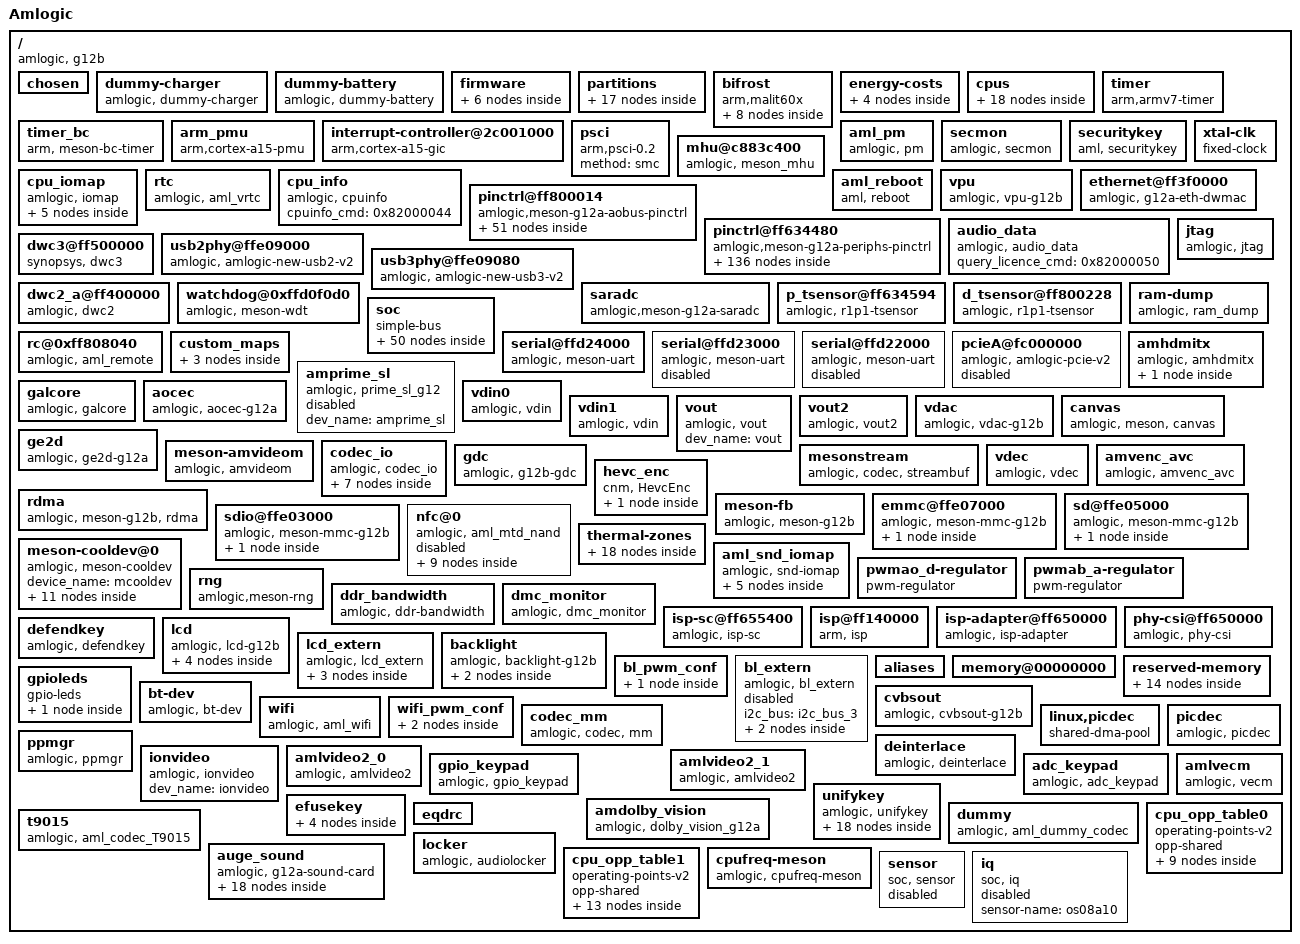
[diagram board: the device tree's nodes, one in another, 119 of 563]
/dts-v1/;

/memreserve/	0x0000000009fe5000 0x0000000000018000;
/ {
	model = "Amlogic";
	amlogic-dt-id = "g12b_w400_b";
	compatible = "amlogic, g12b";
	interrupt-parent = <0x01>;
	#address-cells = <0x01>;
	#size-cells = <0x01>;

	// 内核启动参数，影响系统初始化行为
	chosen {
		bootargs = "
		// 指定 init 程序路径
		init=/init
		// 串口输出设置
		console=ttyS0,115200
		// 禁用串口挂起
		no_console_suspend
		// 启用早期串口调试
		earlycon=aml-uart,0xff803000
		// 启用崩溃日志记录
		ramoops.pstore_en=1
		// 设置记录大小
		ramoops.record_size=0x8000
	 	// 设置控制台日志大小
		ramoops.console_size=0x4000
		// HDR 显示策略
		hdr_policy=1
		// 启用 USB OTG 模式
		hdr_priority= otg_device=1
		// 设置重启模式
		reboot_mode_android=normal
		// logo 显示设置
		logo=osd0,loaded,0x3d800000
		// 帧缓冲区分辨率
		fb_width=1920 fb_height=1080
		// 视频输出设置
		vout=576cvbs,enable
		// LCD 面板类型与控制参数
		panel_type=lcd_2 lcd_ctrl=0x00000083
		// HDMI 输出设置
		hdmitx=,444,12bit hdmimode=1080p60hz hdmichecksum=0x00000000
		// Dolby Vision 设置
		dolby_vision_on=0
		// 分数帧率策略
		frac_rate_policy=1
		// 启用 EDID 读取
		hdmi_read_edid=1
		// CVBS 模式
		cvbsmode=576cvbs
		// OSD 和视频反转设置
		osd_reverse=0 video_reverse=0
		// IRQ 检查开关
		irq_check_en=0
		// SELinux 强制模式
		androidboot.selinux=enforcing
		// 是否首次启动
		androidboot.firstboot=0
		// 禁用 JTAG
		jtag=disable
		// 硬件平台标识
		androidboot.hardware=amlogic
		// 启动引导程序版本
		androidboot.bootloader=U-Boot 2015.01
		 // 基带信息
		androidboot.build.expect.baseband=N/A
		// 设备序列号
		androidboot.serialno=DZXB3P4213004936
		// MAC 地址
		mac=4C:91:7A:5F:F8:5A androidboot.mac=4C:91:7A:5F:F8:5A
		// OEM 自定义参数
		androidboot.oem.key1=ATV00104319
		// RPMB 安全存储状态
		androidboot.rpmb_state=1
		// 根文件系统挂载为只读
		ro
		// 等待根文件系统挂载
		rootwait
		// 跳过 initramfs 阶段
		skip_initramfs
		// DTBO 索引
		androidboot.dtbo_idx=0
		 // 指定根文件系统位置和构建类型
		--cmdline root=/dev/mmcblk0p18 buildvariant=user";
	};

	// 虚拟充电器
	dummy-charger {
		// 启用虚拟充电器设备（用于无电池设备）
		status = "okay";
		// 兼容字符串，匹配驱动
		compatible = "amlogic, dummy-charger";
	};

	// 虚拟电池
	dummy-battery {
		// 启用虚拟电池设备
		status = "okay";
		compatible = "amlogic, dummy-battery";
	};

	// 固件分区挂载信息
	firmware {

		android {
			compatible = "android,firmware";

			vbmeta {
				// Android Verified Boot 元数据配置
				compatible = "android,vbmeta";
				parts = "vbmeta,boot,system,vendor";
				by_name_prefix = "/dev/block";
			};

			fstab {
				compatible = "android,fstab";

				vendor {
					// 挂载 vendor 分区
					compatible = "android,vendor";
					dev = "/dev/block/vendor";
					type = "ext4";
					mnt_flags = "ro,barrier=1,inode_readahead_blks=8";
					fsmgr_flags = "wait";
				};

				product {
					// 挂载 product 分区
					compatible = "android,product";
					dev = "/dev/block/product";
					type = "ext4";
					mnt_flags = "ro,barrier=1,inode_readahead_blks=8";
					fsmgr_flags = "wait";
				};

				odm {
					// 挂载 odm 分区
					compatible = "android,odm";
					dev = "/dev/block/odm";
					type = "ext4";
					mnt_flags = "ro,barrier=1,inode_readahead_blks=8";
					fsmgr_flags = "wait";
				};
			};
		};
	};

	// 分区信息
	partitions {
		// 总分区数量（十六进制 0x11 = 十进制 17）
		parts = <0x11>;

		// 每个 part-x 都是一个分区的 phandle 引用
		part-0 = <0x02>;  // logo 分区
		part-1 = <0x03>;  // recovery 分区
		part-2 = <0x04>;  // misc 分区
		part-3 = <0x05>;  // dtbo 分区
		part-4 = <0x06>;  // cri_data 分区
		part-5 = <0x07>;  // param 分区
		part-6 = <0x08>;  // boot 分区
		part-7 = <0x09>;  // rsv 保留分区
		part-8 = <0x0a>;  // metadata 分区
		part-9 = <0x0b>;  // vbmeta 分区
		part-10 = <0x0c>; // tee 安全执行环境分区
		part-11 = <0x0d>; // vendor 分区
		part-12 = <0x0e>; // odm 分区
		part-13 = <0x0f>; // system 系统分区
		part-14 = <0x10>; // product 产品分区
		part-15 = <0x11>; // cache 缓存分区
		part-16 = <0x12>; // data 用户数据分区

		// partitions 节点的 phandle 引用
		phandle = <0xa4>;

		// 以下是每个分区的定义，包括名称、大小、掩码等
		logo {
			pname = "logo";              // 分区名称
			size = <0x00 0x800000>;      // 分区大小（8MB）
			mask = <0x01>;               // 掩码（访问权限或标志）
			phandle = <0x02>;            // 分区引用 ID
		};

		recovery {
			pname = "recovery";
			size = <0x00 0x1800000>;     // 24MB
			mask = <0x01>;
			phandle = <0x03>;
		};

		misc {
			pname = "misc";
			size = <0x00 0x800000>;      // 8MB
			mask = <0x01>;
			phandle = <0x04>;
		};

		dtbo {
			pname = "dtbo";              // 设备树覆盖分区
			size = <0x00 0x800000>;
			mask = <0x01>;
			phandle = <0x05>;
		};

		cri_data {
			pname = "cri_data";          // Critical data 分区
			size = <0x00 0x800000>;
			mask = <0x02>;
			phandle = <0x06>;
		};

		rsv {
			pname = "rsv";               // 保留分区
			size = <0x00 0x1000000>;
			mask = <0x01>;
			phandle = <0x09>;
		};

		metadata {
			pname = "metadata";          // 元数据分区
			size = <0x00 0x1000000>;
			mask = <0x01>;
			phandle = <0x0a>;
		};

		vbmeta {
			pname = "vbmeta";            // Verified Boot 元数据
			size = <0x00 0x200000>;      // 2MB
			mask = <0x01>;
			phandle = <0x0b>;
		};

		param {
			pname = "param";             // 参数配置分区
			size = <0x00 0x1000000>;     // 16MB
			mask = <0x02>;
			phandle = <0x07>;
		};

		boot {
			pname = "boot";              // 启动镜像分区
			size = <0x00 0x1000000>;     // 16MB
			mask = <0x01>;
			phandle = <0x08>;
		};

		tee {
			pname = "tee";              // TrustZone 分区
			size = <0x00 0x2000000>;    // 32MB
			mask = <0x01>;
			phandle = <0x0c>;
		};

		vendor {
			pname = "vendor";           // 供应商分区
			size = <0x00 0x40000000>;   // 1GB
			mask = <0x01>;
			phandle = <0x0d>;
		};

		odm {
			pname = "odm";              // OEM Device Manufacturer 分区
			size = <0x00 0x8000000>;    // 128MB
			mask = <0x01>;
			phandle = <0x0e>;
		};

		system {
			pname = "system";           // Android 系统分区
			size = <0x00 0x80000000>;   // 2GB
			mask = <0x01>;
			phandle = <0x0f>;
		};

		product {
			pname = "product";          // 产品定制分区
			size = <0x00 0x8000000>;    // 128MB
			mask = <0x01>;
			phandle = <0x10>;
		};

		cache {
			pname = "cache";            // 缓存分区
			size = <0x00 0x60000000>;   // 1.5GB
			mask = <0x02>;
			phandle = <0x11>;
		};

		data {
			pname = "data";             // 用户数据分区
			size = <0xffffffff 0xffffffff>;// 动态分配最大空间
			mask = <0x04>;
			phandle = <0x12>;
		};
	};

	// Amlogic G12B 平台上的 Mali GPU（Midgard 架构）的硬件资源、时钟、DVFS 配置等。
	bifrost {
		// 兼容字符串，匹配驱动（Mali-T60x/T6xx/Midgard 系列）
		compatible = "arm,malit60x\0arm,malit6xx\0arm,mali-midgard";

		// cooling-cells 表示散热设备的参数数量
		#cooling-cells = <0x02>;

		// GPU 寄存器地址映射（多个区域）
		reg = <0xffe40000 0x4000 0xffd01000 0x1000 0xff800000 0x1000 0xff63c000 0x1000 0xffd01000 0x1000>;

		// 中断控制器引用
		interrupt-parent = <0x01>;

		// GPU、MMU、JOB 的中断号及类型
		interrupts = <0x00 0xa0 0x04 0x00 0xa1 0x04 0x00 0xa2 0x04>;
		interrupt-names = "GPU\0MMU\0JOB";

		// PP（Pixel Processor）数量
		num_of_pp = <0x02>;

		// SCMPP（Shader Core Multi PP）配置
		sc_mpp = <0x01>;

		// GPU 时钟源配置（引用 clock-controller）
		clocks = <0x13 0x83 0x13 0x07>;
		clock-names = "gpu_mux\0gp0_pll";

		// DVFS 表引用（phandle）
		tbl = <0x14 0x15 0x16 0x17 0x18 0x18>;

		// 系统一致性设置（通常为 0 表示关闭）
		system-coherency = <0x00>;

		// 节点引用句柄
		phandle = <0xa5>;

		// 以下是不同频率下的 DVFS 配置（动态电压频率调整）
		clk125_cfg {
			clk_freq = <0x7735940>;           // 125MHz
			clk_parent = "fclk_div4";         // 时钟父源
			clkp_freq = <0x1dcd6500>;         // 父源频率（500MHz）
			clk_reg = <0xa03>;                // 时钟寄存器地址
			voltage = <0x47e>;                // 电压值（单位微伏）
			keep_count = <0x05>;              // 保持周期
			threshold = <0x1e 0x78>;          // 温度或负载阈值
			phandle = <0xa6>;
		};

		dvfs250_cfg {
			clk_freq = <0xee6b280>;           // 250MHz
			clk_parent = "fclk_div4";
			clkp_freq = <0x1dcd6500>;
			clk_reg = <0xa01>;
			voltage = <0x47e>;
			keep_count = <0x05>;
			threshold = <0x50 0xaa>;
			phandle = <0xa7>;
		};

		dvfs285_cfg {
			clk_freq = <0x1107a76d>;          // 285MHz
			clk_parent = "fclk_div7";
			clkp_freq = <0x1107a76d>;
			clk_reg = <0xe00>;
			voltage = <0x47e>;
			keep_count = <0x05>;
			threshold = <0x64 0xbe>;
			phandle = <0x14>;
		};

		dvfs400_cfg {
			clk_freq = <0x17d78400>;          // 400MHz
			clk_parent = "fclk_div5";
			clkp_freq = <0x17d78400>;
			clk_reg = <0xc00>;
			voltage = <0x47e>;
			keep_count = <0x05>;
			threshold = <0x98 0xcf>;
			phandle = <0x15>;
		};

		dvfs500_cfg {
			clk_freq = <0x1dcd6500>;          // 500MHz
			clk_parent = "fclk_div4";
			clkp_freq = <0x1dcd6500>;
			clk_reg = <0xa00>;
			voltage = <0x47e>;
			keep_count = <0x05>;
			threshold = <0xb4 0xdc>;
			phandle = <0x16>;
		};

		dvfs666_cfg {
			clk_freq = <0x27bc86aa>;          // 666MHz
			clk_parent = "fclk_div3";
			clkp_freq = <0x27bc86aa>;
			clk_reg = <0x800>;
			voltage = <0x47e>;
			keep_count = <0x05>;
			threshold = <0xd2 0xec>;
			phandle = <0x17>;
		};

		dvfs800_cfg {
			clk_freq = <0x2faf0800>;          // 800MHz
			clk_parent = "fclk_div2p5";
			clkp_freq = <0x2faf0800>;
			clk_reg = <0x600>;
			voltage = <0x47e>;
			keep_count = <0x05>;
			threshold = <0xe6 0xff>;
			phandle = <0x18>;
		};

		dvfs850_cfg {
			clk_freq = <0x326cef80>;          // 850MHz
			clk_parent = "gp0_pll";
			clkp_freq = <0x326cef80>;
			clk_reg = <0x200>;
			voltage = <0x47e>;
			keep_count = <0x05>;
			threshold = <0xe6 0xff>;
			phandle = <0xa8>;
		};
	};

	// CPU 频率下的能耗信息
	energy-costs {
		// LITTLE 核心能耗模型
		core-cost0 {
			busy-cost-data = <0x36 0x11 0x87 0x6e 0x10e 0xca 0x168 0x108 0x21c 0x18c 0x288 0x1d6 0x2f3 0x22d 0x330 0x26c 0x364 0x2bb 0x398 0x2f7 0x3cc 0x333 0x406 0x377 0x440 0x3a9 0x46e 0x3d0 0x4a8 0x418>;
			idle-cost-data = <0x05 0x00 0x00>;
			phandle = <0x23>;
		};
		// big 核心能耗模型
		core-cost1 {
			busy-cost-data = <0x21 0x04 0x53 0x17 0xa6 0x29 0xdd 0x36 0x14c 0x4e 0x18f 0x5c 0x1d1 0x74 0x1f7 0x87 0x217 0xa2 0x237 0xb8 0x257 0xe0 0x277 0x117>;
			idle-cost-data = <0x03 0x00 0x00>;
			phandle = <0x1f>;
		};
		// LITTLE 集群能耗模型
		cluster-cost0 {
			busy-cost-data = <0x36 0x11 0x87 0x14 0x10e 0x19 0x168 0x1b 0x21c 0x23 0x288 0x28 0x2f3 0x31 0x330 0x39 0x364 0x36 0x398 0x40 0x3cc 0x4b 0x406 0x56 0x440 0x61 0x46e 0x6c 0x4a8 0x6e>;
			idle-cost-data = <0x0a 0x0a 0x00>;
			phandle = <0x24>;
		};
		// big 集群能耗模型
		cluster-cost1 {
			busy-cost-data = <0x21 0x07 0x53 0x08 0xa6 0x09 0xdd 0x0a 0x14c 0x0d 0x18f 0x0f 0x1d1 0x13 0x1f7 0x17 0x217 0x1a 0x237 0x1f 0x257 0x24 0x277 0x2a>;
			idle-cost-data = <0x06 0x06 0x00>;
			phandle = <0x20>;
		};
	};

	// CPU 拓扑、频率、电源、时钟、EAS 能耗模型、空闲状态
	cpus {
		// 每个 CPU 的地址单元数量
		#address-cells = <0x01>;
		// CPU 节点不需要 size 单元
		#size-cells = <0x00>;
		// 节点引用句柄
		phandle = <0xa9>;

		// CPU 拓扑映射
		cpu-map {

			cluster0 {
				phandle = <0xaa>;
				// Cortex-A53 核心 0
				core0 {
					cpu = <0x19>;
				};
				// Cortex-A53 核心 1
				core1 {
					cpu = <0x1a>;
				};
			};

			cluster1 {
				phandle = <0xab>;
				// Cortex-A73 核心 0
				core0 {
					cpu = <0x1b>;
				};
				// Cortex-A73 核心 1
				core1 {
					cpu = <0x1c>;
				};
				// Cortex-A73 核心 2
				core2 {
					cpu = <0x1d>;
				};
				// Cortex-A73 核心 3
				core3 {
					cpu = <0x1e>;
				};
			};
		};
		// Cortex-A53 核心 0
		cpu@0 {
			device_type = "cpu";
			compatible = "arm,cortex-a53\0arm,armv8";
			// CPU ID
			reg = <0x00>;
			// 使用 PSCI 启动
			enable-method = "psci";
			// 引用 core-cost1 和 cluster-cost1
			sched-energy-costs = <0x1f 0x20>;
			// 时钟源引用
			clocks = <0x13 0x17 0x13 0x16 0x13 0xee>;
			clock-names = "core_clk\0low_freq_clk_parent\0high_freq_clk_parent";
			// DVFS 表引用
			operating-points-v2 = <0x21>;
			// 电源管理器引用
			cpu-supply = <0x22>;
			// 电压容差
			voltage-tolerance = <0x00>;
			 // 时钟切换延迟（单位微秒）
			clock-latency = <0xc350>;
			phandle = <0x19>;
		};
		// Cortex-A53 核心 1
		cpu@1 {
			device_type = "cpu";
			compatible = "arm,cortex-a53\0arm,armv8";
			reg = <0x01>;
			enable-method = "psci";
			sched-energy-costs = <0x1f 0x20>;
			clocks = <0x13 0x17 0x13 0x16 0x13 0xee>;
			clock-names = "core_clk\0low_freq_clk_parent\0high_freq_clk_parent";
			operating-points-v2 = <0x21>;
			cpu-supply = <0x22>;
			voltage-tolerance = <0x00>;
			clock-latency = <0xc350>;
			phandle = <0x1a>;
		};
		// Cortex-A73 核心 0
		cpu@100 {
			device_type = "cpu";
			compatible = "arm,cortex-a73\0arm,armv8";
			reg = <0x100>;
			enable-method = "psci";
			// 引用 core-cost0 和 cluster-cost0
			sched-energy-costs = <0x23 0x24>;
			clocks = <0x13 0xde 0x13 0xdd 0x13 0x00>;
			clock-names = "core_clk\0low_freq_clk_parent\0high_freq_clk_parent";
			operating-points-v2 = <0x25>;
			cpu-supply = <0x26>;
			voltage-tolerance = <0x00>;
			clock-latency = <0xc350>;
			phandle = <0x1b>;
		};
		// Cortex-A73 核心 1
		cpu@101 {
			device_type = "cpu";
			compatible = "arm,cortex-a73\0arm,armv8";
			reg = <0x101>;
			enable-method = "psci";
			sched-energy-costs = <0x23 0x24>;
			clocks = <0x13 0xde 0x13 0xdd 0x13 0x00>;
			clock-names = "core_clk\0low_freq_clk_parent\0high_freq_clk_parent";
			operating-points-v2 = <0x25>;
			cpu-supply = <0x26>;
			voltage-tolerance = <0x00>;
			clock-latency = <0xc350>;
			phandle = <0x1c>;
		};
		// Cortex-A73 核心 2
		cpu@102 {
			device_type = "cpu";
			compatible = "arm,cortex-a73\0arm,armv8";
			reg = <0x102>;
			enable-method = "psci";
			sched-energy-costs = <0x23 0x24>;
			clocks = <0x13 0xde 0x13 0xdd 0x13 0x00>;
			clock-names = "core_clk\0low_freq_clk_parent\0high_freq_clk_parent";
			operating-points-v2 = <0x25>;
			cpu-supply = <0x26>;
			voltage-tolerance = <0x00>;
			clock-latency = <0xc350>;
			phandle = <0x1d>;
		};
		// Cortex-A73 核心 3
		cpu@103 {
			device_type = "cpu";
			compatible = "arm,cortex-a73\0arm,armv8";
			reg = <0x103>;
			enable-method = "psci";
			sched-energy-costs = <0x23 0x24>;
			clocks = <0x13 0xde 0x13 0xdd 0x13 0x00>;
			clock-names = "core_clk\0low_freq_clk_parent\0high_freq_clk_parent";
			operating-points-v2 = <0x25>;
			cpu-supply = <0x26>;
			voltage-tolerance = <0x00>;
			clock-latency = <0xc350>;
			phandle = <0x1e>;
		};
		// 空闲状态定义
		idle-states {
			// 使用 PSCI 进入低功耗状态
			entry-method = "arm,psci";

			cpu-sleep-0 {
				compatible = "arm,idle-state";
				// CPU 层级 suspend 参数
				arm,psci-suspend-param = <0x10000>;
				local-timer-stop;
				// 进入延迟（8000us）
				entry-latency-us = <0x1f40>;
				// 退出延迟
				exit-latency-us = <0x1f40>;
				// 最小驻留时间（20000us）
				min-residency-us = <0x4e20>;
				phandle = <0xac>;
			};

			cluster-sleep-0 {
				compatible = "arm,idle-state";
				// 集群 suspend 参数
				arm,psci-suspend-param = <0x1010000>;
				local-timer-stop;
				// 进入延迟（9000us）
				entry-latency-us = <0x2328>;
				// 退出延迟
				exit-latency-us = <0x2328>;
				// 最小驻留时间（25000us）
				min-residency-us = <0x61a8>;
				phandle = <0xad>;
			};
		};
	};

	// 通用定时器
	timer {
		// 表示使用 ARMv7 架构的通用定时器（适用于 ARMv8 向下兼容）
		compatible = "arm,armv7-timer";
		interrupts = <0x01 0x0d 0xff08 0x01 0x0e 0xff08 0x01 0x0b 0xff08 0x01 0x0a 0xff08>;
	};

	// Meson 平台定时器
	timer_bc {
		// Meson 平台专用定时器驱动
		compatible = "arm, meson-bc-timer";
		reg = <0xffd0f190 0x04                // TimerF 控制寄存器
			0xffd0f194 0x04>;              // TimerF 值寄存器
		timer_name = "Meson TimerF";         // 定时器名称（用于日志或调试）
		clockevent-rating = <0x12c>;         // 定时器评分（300），用于 clockevent 选择
		clockevent-shift = <0x14>;           // 精度位移（20）
		clockevent-features = <0x23>;        // 支持的功能位（bitmask）
		interrupts = <0x00 0x3c 0x01>;        // 中断号 0x3c（60），类型为 level-high
		bit_enable = <0x10>;                 // 启用位（寄存器中的 bit 位置）
		bit_mode = <0x0c>;                   // 模式位（例如周期/单次）
		bit_resolution = <0x00>;            // 分辨率位（通常为 0 表示默认）
	};

	// 性能监控单元（PMU）
	arm_pmu {
		compatible = "arm,cortex-a15-pmu";   // 使用 Cortex-A15 PMU 驱动（适用于 A73/A53）
		clusterb-enabled;                    // 启用第二集群（big 核心）
		interrupts = <0x00 0x89 0x04         // LITTLE 核心 PMU 中断（137）
					0x00 0xab 0x04>;       // big 核心 PMU 中断（171）
		reg = <0xff634680 0x04               // LITTLE 核心 PMU 寄存器
			0xff6347c0 0x04>;             // big 核心 PMU 寄存器
		cpumasks = <0x03 0x3c>;              // LITTLE: 0x03 (CPU0/1), big: 0x3c (CPU2–5)
		relax-timer-ns = <0x989680>;         // 100ms（用于调度器放宽采样间隔）
		max-wait-cnt = <0x2710>;             // 最大等待计数（10000）
	};

	// GIC 中断控制器
	interrupt-controller@2c001000 {
		compatible = "arm,cortex-a15-gic\0arm,cortex-a9-gic";  // 支持 A15 和 A9 架构的 GIC
		#interrupt-cells = <0x03>;      // 中断描述格式为 <type number flags>
		#address-cells = <0x00>;        // 无子节点地址单元
		interrupt-controller;           // 声明为中断控制器
		reg = <0xffc01000 0x1000        // Distributor 寄存器
			0xffc02000 0x100>;       // CPU Interface 寄存器
		interrupts = <0x01 0x09 0xf04>; // SPI 中断号 9，flags 为 level-high
		phandle = <0x01>;               // 引用句柄
	};

	// 电源状态协调接口
	psci {
		compatible = "arm,psci-0.2";  // 使用 PSCI v0.2 协议
		method = "smc";               // 通过 SMC（Secure Monitor Call）调用
	};

	// Amlogic 平台电源管理器
	aml_pm {
		compatible = "amlogic, pm";     // Amlogic 专用电源管理驱动
		status = "okay";                // 启用状态
		device_name = "aml_pm";         // 设备名称
		debug_reg = <0xff8000a8>;       // 调试寄存器地址
		exit_reg = <0xff80023c>;        // 退出寄存器地址（可能用于 suspend/resume）
	};

	// 安全监控模块
	secmon {
		compatible = "amlogic, secmon";     // Amlogic 安全监控驱动
		memory-region = <0x27>;             // 保留内存区域（通常为 TZRAM）
		in_base_func = <0x82000020>;        // SMC 输入函数号
		out_base_func = <0x82000021>;       // SMC 输出函数号
		reserve_mem_size = <0x300000>;      // 预留内存大小（3MB）
		clear_range = <0x5100000 0x200000>; // 清除范围（地址 + 大小）
	};

	// 安全密钥服务接口
	securitykey {
		compatible = "aml, securitykey";    // Amlogic 安全密钥驱动
		storage_query = <0x82000060>;       // 查询密钥
		storage_read = <0x82000061>;        // 读取密钥
		storage_write = <0x82000062>;       // 写入密钥
		storage_tell = <0x82000063>;        // 获取密钥位置
		storage_verify = <0x82000064>;      // 验证密钥
		storage_status = <0x82000065>;      // 获取状态
		storage_list = <0x82000067>;        // 列出密钥
		storage_remove = <0x82000068>;      // 删除密钥
		storage_in_func = <0x82000023>;     // 输入函数
		storage_out_func = <0x82000024>;    // 输出函数
		storage_block_func = <0x82000025>;  // 块操作函数
		storage_size_func = <0x82000027>;   // 获取密钥大小
		storage_set_enctype = <0x8200006a>; // 设置加密类型
		storage_get_enctype = <0x8200006b>; // 获取加密类型
		storage_version = <0x8200006c>;     // 获取版本信息
	};

	// Message Handling Unit（CPU ↔ SCP 通信）
	mhu@c883c400 {
		compatible = "amlogic, meson_mhu";         // Amlogic MHU 驱动
		reg = <0xff63c400 0x4c                      // MHU 控制寄存器
			0xfffe7000 0x800>;                   // SCP 通信区域
		interrupts = <0x00 0xd1 0x01                // 中断 209（低通道）
					0x00 0xd2 0x01>;              // 中断 210（高通道）
		#mbox-cells = <0x01>;                       // 每个邮箱使用一个 cell
		mbox-names = "cpu_to_scp_low\0cpu_to_scp_high";  // 邮箱名称
		mboxes = <0x28 0x00 0x28 0x01>;             // 邮箱通道引用
		phandle = <0x28>;
	};

	// CPU I/O 映射区域
	cpu_iomap {
		compatible = "amlogic, iomap";
		#address-cells = <0x01>;
		#size-cells = <0x01>;
		ranges;

		io_cbus_base     { reg = <0xffd00000 0x26000>; };
		io_apb_base      { reg = <0xffe01000 0x7f000>; };
		io_aobus_base    { reg = <0xff800000 0xb000>; };
		io_vapb_base     { reg = <0xff900000 0x50000>; };
		io_hiu_base      { reg = <0xff63c000 0x2000>; };
	};

	// 固定晶振时钟源
	xtal-clk {
		compatible = "fixed-clock";
		clock-frequency = <0x16e3600>;         // 24MHz（0x16e3600）
		clock-output-names = "xtal";           // 时钟名称
		#clock-cells = <0x00>;                 // 无参数
		phandle = <0x2d>;
	};

	// 实时时钟模块
	rtc {
		compatible = "amlogic, aml_vrtc";
		alarm_reg_addr = <0xff8000a8>;         // 闹钟寄存器地址
		timer_e_addr = <0xffd0f188>;           // TimerE 地址
		init_date = "2019/01/01";              // 初始日期
		status = "okay";
	};

	// CPU 信息接口
	cpu_info {
		compatible = "amlogic, cpuinfo";
		status = "okay";
		cpuinfo_cmd = <0x82000044>;            // SMC 命令号，用于获取 CPU 信息
	};

	// 系统重启与关机控制器
	aml_reboot {
		compatible = "aml, reboot";
		sys_reset = <0x84000009>;              // SMC 命令号：重启
		sys_poweroff = <0x84000008>;           // SMC 命令号：关机
	};

	// 视频处理单元
	vpu {
		compatible = "amlogic, vpu-g12b";      // G12B 平台 VPU 驱动
		dev_name = "vpu";
		status = "okay";
		clocks = <0x13 0x95 0x13 0x4c 0x13 0x87 0x13 0x8b 0x13 0x8c>;  // 时钟源引用
		clock-names = "vapb_clk\0vpu_intr_gate\0vpu_clk0\0vpu_clk1\0vpu_clk";
		clk_level = <0x07>;                    // 时钟等级（性能等级）
	};

	// ethernet@ff3f0000 节点是 Amlogic G12A 平台上的以太网控制器
	ethernet@ff3f0000 {
		compatible = "amlogic, g12a-eth-dwmac", "snps,dwmac";  // 使用 Amlogic 定制的 DWMAC 驱动
		reg = <0xff3f0000 0x10000        // eth_base: MAC 寄存器区域
			0xff634540 0x08           // eth_cfg: 配置寄存器
			0xff64c000 0xa0           // eth_pll: PLL 控制寄存器
			0xffd01008 0x04>;         // eth_reset: 复位寄存器
		reg-names = "eth_base", "eth_cfg", "eth_pll", "eth_reset";

		interrupts = <0x00 0x08 0x01>;   // SPI 中断号 8，类型为 level-high
		interrupt-names = "macirq";     // MAC 中断名称

		status = "okay";                // 启用设备

		clocks = <0x13 0x38>;           // 时钟控制器引用（ethclk81）
		clock-names = "ethclk81";       // 时钟名称

		pll_val = <0x09c0040a 0x927e0000 0xac5f49e5>;  // PLL 初始化值（用于 PHY 时钟）
		analog_val = <0x20200000 0x0000c000 0x23>;     // 模拟电路配置（PHY 校准相关）

		pinctrl-names = "external_eth_pins";          // 引脚配置名称
		pinctrl-0 = <0x29>;                           // 引脚控制器引用

		mc_val = <0x1621>;            // MAC 控制寄存器值（可能用于 TX/RX 配置）
		cali_val = <0x60000>;         // PHY 校准值（用于 RX/TX 延迟调整）
		rx_delay = <0x01>;            // 接收延迟（单位可能为 ns 或寄存器位）
		auto_cali_idx = <0x26>;       // 自动校准索引（用于动态 PHY 调整）

		internal_phy = <0x00>;        // 使用外部 PHY（0 表示关闭内部 PHY）

		phandle = <0xae>;             // 节点引用句柄
	};

	// AO（Always-On）域引脚控制器配置，涵盖了 UART、I²C、PWM、CEC、JTAG、红外、SPDIF 等功能的引脚复用设置。这是系统低功耗域中最关键的引脚管理模块之一。
	pinctrl@ff800014 {
		// G12A AO 域 pinctrl 驱动
		compatible = "amlogic,meson-g12a-aobus-pinctrl";
		#address-cells = <0x01>;
		#size-cells = <0x01>;
		ranges;
		phandle = <0xaf>;

		// AO GPIO 控制器
		ao-bank@ff800014 {
			reg = <0xff800014 0x08        // mux 控制寄存器
				0xff800024 0x14        // gpio 状态寄存器
				0xff80001c 0x08>;      // drive-strength 寄存器
			reg-names = "mux", "gpio", "drive-strength";
			gpio-controller;
			#gpio-cells = <0x02>;         // <pin offset, flags>
			phandle = <0x61>;
		};

		// UART 配置：ao_uart、ao_b_uart、sd_to_ao_uart_pins、sd_to_ao_uart_clr_pins
		// I²C 配置: ao_i2c_pins1、ao_i2c_pins2、ao_i2c_slave_pins
		// PWM 配置：pwm_ao_a、pwm_ao_a_hiz、pwm_ao_b、pwm_ao_c_pins1、pwm_ao_c_pins2、pwm_ao_c_hiz、pwm_ao_d_pins1、pwm_ao_d_pins2、pwm_ao_d_pins3、pwm_a_e2
		// CEC（HDMI 控制）配置：ao_ceca、ao_cecb
		// JTAG 配置：jtag_apao_pin
		// 红外与遥控配置；remote_pin、irblaster_pin、irblaster_pin1
		// SPDIF 配置：spdifout、spdifout_a_mute

		ao_uart {
			phandle = <0xb0>;
			// 引脚复用配置
			mux {
				groups = "uart_ao_tx_a\0uart_ao_rx_a";
				function = "uart_ao_a";
			};
		};

		ao_b_uart {
			phandle = <0x35>;

			mux {
				groups = "uart_ao_tx_b_2\0uart_ao_rx_b_3";
				function = "uart_ao_b";
			};
		};

		ao_i2c_pins1 {
			phandle = <0xb1>;

			mux {
				groups = "i2c_ao_sck\0i2c_ao_sda";
				function = "i2c_ao";
				bias-pull-up;
				drive-strength = <0x02>;
			};
		};

		ao_i2c_pins2 {
			phandle = <0xb2>;

			mux {
				groups = "i2c_ao_sck_e\0i2c_ao_sda_e";
				function = "i2c_ao";
				bias-pull-up;
				drive-strength = <0x02>;
			};
		};

		ao_i2c_slave_pins {
			phandle = <0x34>;

			mux {
				groups = "i2c_ao_slave_sck\0i2c_ao_slave_sda";
				function = "i2c_ao_slave";
			};
		};

		pwm_ao_a {
			phandle = <0xb3>;

			mux {
				groups = "pwm_ao_a";
				function = "pwm_ao_a";
			};
		};

		pwm_ao_a_hiz {
			phandle = <0xb4>;

			mux {
				groups = "pwm_ao_a_hiz";
				function = "pwm_ao_a";
			};
		};

		pwm_ao_b {
			phandle = <0xb5>;

			mux {
				groups = "pwm_ao_b";
				function = "pwm_ao_b";
			};
		};

		pwm_ao_c_pins1 {
			phandle = <0xb6>;

			mux {
				groups = "pwm_ao_c_4";
				function = "pwm_ao_c";
			};
		};

		pwm_ao_c_pins2 {
			phandle = <0xb7>;

			mux {
				groups = "pwm_ao_c_6";
				function = "pwm_ao_c";
			};
		};

		pwm_ao_c_hiz {
			phandle = <0xb8>;

			mux {
				groups = "pwm_ao_c_hiz_4";
				function = "pwm_ao_c";
			};
		};

		pwm_ao_d_pins1 {
			phandle = <0xb9>;

			mux {
				groups = "pwm_ao_d_5";
				function = "pwm_ao_d";
			};
		};

		pwm_ao_d_pins2 {
			phandle = <0xba>;

			mux {
				groups = "pwm_ao_d_10";
				function = "pwm_ao_d";
			};
		};

		pwm_ao_d_pins3 {
			phandle = <0x6f>;

			mux {
				groups = "pwm_ao_d_e";
				function = "pwm_ao_d";
			};
		};

		ao_ceca {
			phandle = <0xbb>;

			mux {
				groups = "cec_ao_a";
				function = "cec_ao";
			};
		};

		ao_cecb {
			phandle = <0xbc>;

			mux {
				groups = "cec_ao_b";
				function = "cec_ao";
			};
		};

		pwm_a_e2 {
			phandle = <0x71>;

			mux {
				groups = "pwm_a_e2";
				function = "pwm_a_gpioe";
			};
		};

		jtag_apao_pin {
			phandle = <0x2e>;

			mux {
				groups = "jtag_a_tdi\0jtag_a_tdo\0jtag_a_clk\0jtag_a_tms";
				function = "jtag_a";
			};
		};

		sd_to_ao_uart_clr_pins {
			phandle = <0x5c>;

			mux {
				groups = "GPIOAO_0\0GPIOAO_1";
				function = "gpio_aobus";
			};
		};

		sd_to_ao_uart_pins {
			phandle = <0x5e>;

			mux {
				groups = "uart_ao_tx_a\0uart_ao_rx_a";
				function = "uart_ao_a";
				bias-pull-up;
				input-enable;
			};
		};

		remote_pin {
			phandle = <0x43>;

			mux {
				groups = "remote_input_ao";
				function = "remote_input_ao";
			};
		};

		irblaster_pin {
			phandle = <0xbd>;

			mux {
				groups = "remote_out_ao";
				function = "remote_out_ao";
			};
		};

		irblaster_pin1 {
			phandle = <0xbe>;

			mux {
				groups = "remote_out_ao9";
				function = "remote_out_ao";
			};
		};

		spdifout {
			phandle = <0x40>;

			mux {
				groups = "spdif_out_ao";
				function = "spdif_out_ao";
			};
		};

		spdifout_a_mute {
			phandle = <0x41>;

			mux {
				groups = "GPIOAO_10";
				function = "gpio_aobus";
			};
		};
	};

	// G12A 平台的主外设引脚控制器（PERIPHS 域），负责管理除 AO 域外的大部分 GPIO 和复用功能。它支持 SD/eMMC、I²C、PWM、SPI、UART、HDMI、Ethernet、音频等模块的引脚配置。包括存储接口（eMMC/SD/NAND/SDIO）、通信接口（I²C/SPI/UART）、音视频接口（HDMI/CEC/TDM/SPDIF）、控制接口（PWM/JTAG）、网络接口（Ethernet）、红外遥控与麦克风输入
	pinctrl@ff634480 {
		compatible = "amlogic,meson-g12a-periphs-pinctrl";
		#address-cells = <0x01>;
		#size-cells = <0x01>;
		ranges;
		phandle = <0xbf>;

		banks@ff6346c0 {
			reg = <0xff6346c0 0x40 0xff6344e8 0x18 0xff634520 0x18 0xff634440 0x4c 0xff634740 0x1c>;
			reg-names = "mux\0pull\0pull-enable\0gpio\0drive-strength";
			gpio-controller;
			#gpio-cells = <0x02>;
			phandle = <0x2c>;
		};

		emmc_clk_cmd_pins {
			phandle = <0x56>;

			mux {
				groups = "emmc_clk\0emmc_cmd";
				function = "emmc";
				input-enable;
				bias-pull-up;
				drive-strength = <0x03>;
			};
		};

		emmc_conf_pull_up {
			phandle = <0x57>;

			mux {
				groups = "emmc_nand_d7\0emmc_nand_d6\0emmc_nand_d5\0emmc_nand_d4\0emmc_nand_d3\0emmc_nand_d2\0emmc_nand_d1\0emmc_nand_d0\0emmc_clk\0emmc_cmd";
				function = "emmc";
				input-enable;
				bias-pull-up;
				drive-strength = <0x03>;
			};
		};

		emmc_conf_pull_done {
			phandle = <0x58>;

			mux {
				groups = "emmc_nand_ds";
				function = "emmc";
				input-enable;
				bias-pull-down;
				drive-strength = <0x03>;
			};
		};

		sd_clk_cmd_pins {
			phandle = <0x5a>;

			mux {
				groups = "sdcard_cmd_c\0sdcard_clk_c";
				function = "sdcard";
				input-enable;
				bias-pull-up;
				drive-strength = <0x03>;
			};
		};

		sd_all_pins {
			phandle = <0x59>;

			mux {
				groups = "sdcard_d0_c\0sdcard_d1_c\0sdcard_d2_c\0sdcard_d3_c\0sdcard_cmd_c\0sdcard_clk_c";
				function = "sdcard";
				input-enable;
				bias-pull-up;
				drive-strength = <0x03>;
			};
		};

		sd_1bit_pins {
			phandle = <0x5b>;

			mux {
				groups = "sdcard_d0_c\0sdcard_cmd_c\0sdcard_clk_c";
				function = "sdcard";
				input-enable;
				bias-pull-up;
				drive-strength = <0x03>;
			};
		};

		ao_to_sd_uart_pins {
			phandle = <0x5d>;

			mux {
				groups = "uart_ao_tx_a_c3\0uart_ao_rx_a_c2";
				function = "uart_ao_a_ee";
				bias-pull-up;
				input-enable;
			};
		};

		sdio_clk_cmd_pins {
			phandle = <0x60>;

			mux {
				groups = "sdio_clk\0sdio_cmd";
				function = "sdio";
				input-enable;
				bias-pull-up;
				drive-strength = <0x03>;
			};
		};

		sdio_all_pins {
			phandle = <0x5f>;

			mux {
				groups = "sdio_d0\0sdio_d1\0sdio_d2\0sdio_d3\0sdio_clk\0sdio_cmd";
				function = "sdio";
				input-enable;
				bias-pull-up;
				drive-strength = <0x03>;
			};
		};

		all_nand_pins {
			phandle = <0x62>;

			mux {
				groups = "emmc_nand_d0\0emmc_nand_d1\0emmc_nand_d2\0emmc_nand_d3\0emmc_nand_d4\0emmc_nand_d5\0emmc_nand_d6\0emmc_nand_d7\0nand_ce0\0nand_ale\0nand_cle\0nand_wen_clk\0nand_ren_wr\0nand_rb0";
				function = "nand";
				input-enable;
			};
		};

		nand_cs {
			phandle = <0x63>;

			mux {
				groups = "nand_ce0";
				function = "nand";
			};
		};

		i2c0_pins1 {
			phandle = <0xc0>;

			mux {
				groups = "i2c0_sda_c\0i2c0_sck_c";
				function = "i2c0";
				bias-pull-up;
				drive-strength = <0x02>;
			};
		};

		i2c0_pins2 {
			phandle = <0x30>;

			mux {
				groups = "i2c0_sda_z0\0i2c0_sck_z1";
				function = "i2c0";
				bias-pull-up;
				drive-strength = <0x02>;
			};
		};

		i2c0_pins3 {
			phandle = <0xc1>;

			mux {
				groups = "i2c0_sda_z7\0i2c0_sck_z8";
				function = "i2c0";
				bias-pull-up;
				drive-strength = <0x02>;
			};
		};

		i2c1_pins1 {
			phandle = <0xc2>;

			mux {
				groups = "i2c1_sda_x\0i2c1_sck_x";
				function = "i2c1";
				bias-pull-up;
				drive-strength = <0x02>;
			};
		};

		i2c1_pins2 {
			phandle = <0xc3>;

			mux {
				groups = "i2c1_sda_h2\0i2c1_sck_h3";
				function = "i2c1";
				bias-pull-up;
				drive-strength = <0x02>;
			};
		};

		i2c1_pins3 {
			phandle = <0xc4>;

			mux {
				groups = "i2c1_sda_h6\0i2c1_sck_h7";
				function = "i2c1";
				bias-pull-up;
				drive-strength = <0x02>;
			};
		};

		i2c2_pins1 {
			phandle = <0xc5>;

			mux {
				groups = "i2c2_sda_x\0i2c2_sck_x";
				function = "i2c2";
				bias-pull-up;
				drive-strength = <0x02>;
			};
		};

		i2c2_pins2 {
			phandle = <0x31>;

			mux {
				groups = "i2c2_sda_z\0i2c2_sck_z";
				function = "i2c2";
				bias-pull-up;
				drive-strength = <0x02>;
			};
		};

		i2c3_pins1 {
			phandle = <0x4f>;

			mux {
				groups = "i2c3_sda_h\0i2c3_sck_h";
				function = "i2c3";
				bias-pull-up;
				drive-strength = <0x02>;
			};
		};

		i2c3_pins2 {
			phandle = <0x33>;

			mux {
				groups = "i2c3_sda_a\0i2c3_sck_a";
				function = "i2c3";
				bias-pull-up;
				drive-strength = <0x02>;
			};
		};

		pwm_a {
			phandle = <0xc6>;

			mux {
				groups = "pwm_a";
				function = "pwm_a";
			};
		};

		pwm_b_pins1 {
			phandle = <0xc7>;

			mux {
				groups = "pwm_b_x7";
				function = "pwm_b";
			};
		};

		pwm_b_pins2 {
			phandle = <0xc8>;

			mux {
				groups = "pwm_b_x19";
				function = "pwm_b";
			};
		};

		pwm_b_pins3 {
			phandle = <0xc9>;

			mux {
				groups = "pwm_b_h";
				function = "pwm_b";
			};
		};

		pwm_b_pins4 {
			phandle = <0xca>;

			mux {
				groups = "pwm_b_z0";
				function = "pwm_b";
			};
		};

		pwm_b_pins5 {
			phandle = <0xcb>;

			mux {
				groups = "pwm_b_z13";
				function = "pwm_b";
			};
		};

		pwm_c_pins1 {
			phandle = <0xcc>;

			mux {
				groups = "pwm_c_c4";
				function = "pwm_c";
			};
		};

		pwm_c_pins2 {
			phandle = <0xcd>;

			mux {
				groups = "pwm_c_x5";
				function = "pwm_c";
			};
		};

		pwm_c_pins3 {
			phandle = <0xce>;

			mux {
				groups = "pwm_c_x8";
				function = "pwm_c";
			};
		};

		pwm_c_pins4 {
			phandle = <0xcf>;

			mux {
				groups = "pwm_c_z";
				function = "pwm_c";
			};
		};

		pwm_d_pins1 {
			phandle = <0xd0>;

			mux {
				groups = "pwm_d_x3";
				function = "pwm_d";
			};
		};

		pwm_d_pins2 {
			phandle = <0xd1>;

			mux {
				groups = "pwm_d_x6";
				function = "pwm_d";
			};
		};

		pwm_d_pins3 {
			phandle = <0xd2>;

			mux {
				groups = "pwm_d_z";
				function = "pwm_d";
			};
		};

		pwm_d_pins4 {
			phandle = <0xd3>;

			mux {
				groups = "pwm_d_a4";
				function = "pwm_d";
			};
		};

		pwm_e {
			phandle = <0x7b>;

			mux {
				groups = "pwm_e";
				function = "pwm_e";
			};
		};

		pwm_f_pins1 {
			phandle = <0xd4>;

			mux {
				groups = "pwm_f_x";
				function = "pwm_f";
			};
		};

		pwm_f_pins2 {
			phandle = <0x77>;

			mux {
				groups = "pwm_f_h";
				function = "pwm_f";
			};
		};

		pwm_f_pins3 {
			phandle = <0xd5>;

			mux {
				groups = "pwm_f_z";
				function = "pwm_f";
			};
		};

		pwm_f_pins4 {
			phandle = <0xd6>;

			mux {
				groups = "pwm_f_a11";
				function = "pwm_f";
			};
		};

		spicc0_pins_x {
			phandle = <0xd7>;

			mux {
				groups = "spi0_mosi_x\0spi0_miso_x\0spi0_clk_x";
				function = "spi0";
				drive-strength = <0x01>;
			};
		};

		spicc1_pins {
			phandle = <0xd8>;

			mux {
				groups = "spi1_mosi\0spi1_miso\0spi1_clk";
				function = "spi1";
				drive-strength = <0x01>;
			};
		};

		a_uart {
			phandle = <0x48>;

			mux {
				groups = "uart_tx_a\0uart_rx_a\0uart_rts_a";
				function = "uart_a";
			};

			mux1 {
				groups = "uart_cts_a";
				function = "uart_a";
				bias-pull-down;
			};
		};

		b_uart {
			phandle = <0x49>;

			mux {
				groups = "uart_tx_b\0uart_rx_b";
				function = "uart_b";
			};
		};

		c_uart {
			phandle = <0x4a>;

			mux {
				groups = "uart_tx_c\0uart_rx_c";
				function = "uart_c";
			};
		};

		hdmitx_hpd {
			phandle = <0x4c>;

			mux {
				groups = "hdmitx_hpd_in";
				function = "hdmitx";
				bias-disable;
			};
		};

		hdmitx_hpd_gpio {
			phandle = <0x4e>;

			mux {
				groups = "GPIOH_1";
				function = "gpio_periphs";
				bias-disable;
			};
		};

		hdmitx_ddc {
			phandle = <0x4d>;

			mux {
				groups = "hdmitx_sda\0hdmitx_sck";
				function = "hdmitx";
				bias-disable;
			};
		};

		ee_ceca {
			phandle = <0x51>;

			mux {
				groups = "cec_ao_a_ee";
				function = "cec_ao_ee";
			};
		};

		ee_cecb {
			phandle = <0x52>;

			mux {
				groups = "cec_ao_b_ee";
				function = "cec_ao_ee";
			};
		};

		internal_eth_pins {
			phandle = <0xd9>;

			mux {
				groups = "eth_link_led\0eth_act_led";
				function = "eth";
			};
		};

		external_eth_pins {
			phandle = <0x29>;

			mux {
				groups = "eth_mdio\0eth_mdc\0eth_rgmii_rx_clk\0eth_rx_dv\0eth_rxd0\0eth_rxd1\0eth_rxd2_rgmii\0eth_rxd3_rgmii\0eth_rgmii_tx_clk\0eth_txd0\0eth_txd1\0eth_txd2_rgmii\0eth_txd3_rgmii";
				function = "eth";
				drive-strength = <0x03>;
			};
		};

		irblaster_pins2 {
			phandle = <0xda>;

			mux {
				groups = "remote_out_h";
				function = "remote_out";
			};
		};

		irblaster_pins3 {
			phandle = <0xdb>;

			mux {
				groups = "remote_out_z";
				function = "remote_out";
			};
		};

		jtag_apee_pin {
			phandle = <0x2f>;

			mux {
				groups = "jtag_b_tdi\0jtag_b_tdo\0jtag_b_clk\0jtag_b_tms";
				function = "jtag_b";
			};
		};

		tdmout_a {
			phandle = <0x38>;

			mux {
				groups = "tdma_sclk\0tdma_fs\0tdma_dout0";
				function = "tdma_out";
			};
		};

		tdmin_a {
			phandle = <0x39>;

			mux {
				groups = "tdma_din1";
				function = "tdma_in";
			};
		};

		tdmb_mclk {
			phandle = <0x3a>;

			mux {
				groups = "mclk0_a";
				function = "mclk0";
				drive-strength = <0x02>;
			};
		};

		tdmout_b {
			phandle = <0x3b>;

			mux {
				groups = "tdmb_sclk\0tdmb_fs\0tdmb_dout0";
				function = "tdmb_out";
				drive-strength = <0x02>;
			};
		};

		tdmin_b {
			phandle = <0x3c>;

			mux {
				groups = "tdmb_din1";
				function = "tdmb_in";
				drive-strength = <0x02>;
			};
		};

		tdmc_mclk {
			phandle = <0x3d>;

			mux {
				groups = "mclk1_a";
				function = "mclk1";
			};
		};

		tdmout_c {
			phandle = <0x3e>;

			mux {
				groups = "tdmc_sclk_a\0tdmc_fs_a\0tdmc_dout0_a";
				function = "tdmc_out";
			};
		};

		tdmin_c {
			phandle = <0x3f>;

			mux {
				groups = "tdmc_din0_a";
				function = "tdmc_in";
			};
		};

		spdifin {
			phandle = <0xdc>;

			mux {
				groups = "spdif_in_h";
				function = "spdif_in";
			};
		};

		pdmin {
			phandle = <0x42>;

			mux {
				groups = "pdm_din0_a\0pdm_din2_a\0pdm_dclk_a";
				function = "pdm";
			};
		};

		bl_pwm_off_pin {
			phandle = <0x78>;

			mux {
				pins = "GPIOH_5";
				function = "gpio_periphs";
				output-high;
			};
		};

		clk12_24_z_pins {
			phandle = <0xa3>;

			mux {
				groups = "clk12_24_z";
				function = "clk12_24_ee";
				drive-strength = <0x03>;
			};
		};
	};

	// 用于音频数据通路许可验证的一个特殊设备节点
	audio_data {
		compatible = "amlogic, audio_data";
		query_licence_cmd = <0x82000050>;
		status = "okay";
		phandle = <0xdd>;
	};

	// Amlogic GXL 平台上用于配置 Synopsys DesignWare Core SuperSpeed USB 3.0 控制器（DWC3）的设备树条目
	dwc3@ff500000 {
		compatible = "synopsys, dwc3";         // 匹配 DWC3 驱动
		status = "okay";                       // 启用设备
		reg = <0xff500000 0x100000>;           // 控制器寄存器地址和大小
		interrupts = <0x00 0x1e 0x04>;         // 中断号（GIC SPI 30）
		usb-phy = <0x2a 0x2b>;                 // 关联的 USB PHY（通常为 USB2 和 USB3 PHY）
		cpu-type = "gxl";                      // 指定 SoC 类型（GXL）
		clock-src = "usb3.0";                  // 时钟源标识
		clocks = <0x13 0x41>;                  // 关联的时钟资源
		clock-names = "dwc_general";           // 时钟名称
		phandle = <0xde>;                      // 引用句柄
	};

	// USB 2.0 PHY控制器
	usb2phy@ffe09000 {
		compatible = "amlogic, amlogic-new-usb2-v2";
		status = "okay";
		reg = <0xffe09000 0x80 0xffd01008 0x100 0xff636000 0x2000 0xff63a000 0x2000>;
		pll-setting-1 = <0x9400414>;
		pll-setting-2 = <0x927e0000>;
		pll-setting-3 = <0xac5f69e5>;
		pll-setting-4 = <0xfe18>;
		pll-setting-5 = <0x8000fff>;
		pll-setting-6 = <0x78000>;
		pll-setting-7 = <0xe0004>;
		pll-setting-8 = <0xe000c>;
		portnum = <0x02>;
		phandle = <0x2a>;
	};

	// USB 3.0 PHY控制器
	usb3phy@ffe09080 {
		compatible = "amlogic, amlogic-new-usb3-v2";
		status = "okay";
		reg = <0xffe09080 0x20>;
		phy-reg = <0xff646000>;
		phy-reg-size = <0x2000>;
		usb2-phy-reg = <0xffe09000>;
		usb2-phy-reg-size = <0x80>;
		interrupts = <0x00 0x10 0x04>;
		clocks = <0x13 0x18>;
		clock-names = "pcie_refpll";
		portnum = <0x01>;
		otg = <0x01>;
		gpio-vbus-power = "GPIOH_6";
		gpios = <0x2c 0x17 0x00>;
		phandle = <0x2b>;
	};

	// DWC2 USB控制器
	dwc2_a@ff400000 {
		compatible = "amlogic, dwc2";
		status = "okay";
		device_name = "dwc2_a";
		reg = <0xff400000 0x40000>;
		interrupts = <0x00 0x1f 0x04>;
		pl-periph-id = <0x00>;
		clock-src = "usb0";
		port-id = <0x00>;
		port-type = <0x02>;
		port-speed = <0x00>;
		port-config = <0x00>;
		port-dma = <0x00>;
		port-id-mode = <0x00>;
		usb-fifo = <0x2d8>;
		cpu-type = "v2";
		phy-reg = <0xffe09000>;
		phy-reg-size = <0xa0>;
		phy-interface = <0x00>;
		clocks = <0x13 0x41 0x13 0x49>;
		clock-names = "usb_general\0usb1";
		controller-type = <0x03>;
		phandle = <0xdf>;
	};

	// 看门狗定时器(WDT)
	watchdog@0xffd0f0d0 {
		compatible = "amlogic, meson-wdt";
		status = "okay";
		default_timeout = <0x0a>;
		reset_watchdog_method = <0x01>;
		reset_watchdog_time = <0x02>;
		shutdown_timeout = <0x0a>;
		firmware_timeout = <0x06>;
		suspend_timeout = <0x06>;
		reg = <0xffd0f0d0 0x10>;
		clock-names = "xtal";
		clocks = <0x2d>;
		phandle = <0xe0>;
	};

	// JTAG调试接口
	jtag {
		compatible = "amlogic, jtag";
		status = "okay";
		select = "disable";
		pinctrl-names = "jtag_apao_pins\0jtag_apee_pins";
		pinctrl-0 = <0x2e>;
		pinctrl-1 = <0x2f>;
	};

	// 逐次逼近型模数转换器(SAR ADC)
	saradc {
		compatible = "amlogic,meson-g12a-saradc";
		status = "okay";
		#io-channel-cells = <0x01>;
		clocks = <0x2d 0x13 0x105>;
		clock-names = "xtal\0saradc_clk";
		interrupts = <0x00 0xc8 0x01>;
		reg = <0xff809000 0x48>;
		phandle = <0x82>;
	};

	// 处理器温度传感器节点‌，用于监测CPU/SoC芯片内部温度
	p_tsensor@ff634594 {
		compatible = "amlogic, r1p1-tsensor";
		device_name = "meson-pthermal";
		status = "okay";
		reg = <0xff634800 0x50 0xff800268 0x04>;
		cal_type = <0x01>;
		cal_a = <0x144>;
		cal_b = <0x1a8>;
		cal_c = <0xc57>;
		cal_d = <0x24c3>;
		rtemp = <0x1c138>;
		interrupts = <0x00 0x23 0x00>;
		clocks = <0x13 0xd6>;
		clock-names = "ts_comp";
		#thermal-sensor-cells = <0x01>;
		phandle = <0x67>;
	};

	// DDR温度传感器节点‌，专门监测内存（DRAM）的工作温度
	d_tsensor@ff800228 {
		compatible = "amlogic, r1p1-tsensor";
		device_name = "meson-dthermal";
		status = "okay";
		reg = <0xff634c00 0x50 0xff800230 0x04>;
		cal_type = <0x01>;
		cal_a = <0x144>;
		cal_b = <0x1a8>;
		cal_c = <0xc57>;
		cal_d = <0x24c3>;
		rtemp = <0x1c138>;
		interrupts = <0x00 0x24 0x00>;
		clocks = <0x13 0xd6>;
		clock-names = "ts_comp";
		#thermal-sensor-cells = <0x01>;
		phandle = <0x6e>;
	};

	// 内存转储功能节点‌，用于系统崩溃时保存关键内存数据到指定存储设备
	ram-dump {
		compatible = "amlogic, ram_dump";
		status = "okay";
		reg = <0xff6345e0 0x04>;
		reg-names = "PREG_STICKY_REG8";
		store_device = "data";
	};

	// soc总线
	soc {
		compatible = "simple-bus";
		#address-cells = <0x01>;
		#size-cells = <0x01>;
		ranges;

		// SoC内部的控制总线子节点
		cbus@ffd00000 {
			compatible = "simple-bus";
			reg = <0xffd00000 0x26000>;
			#address-cells = <0x01>;
			#size-cells = <0x01>;
			ranges = <0x00 0xffd00000 0x26000>;
			phandle = <0xe1>;

			interrupt-controller@f080 {
				compatible = "amlogic,meson-gpio-intc\0amlogic,meson-g12a-gpio-intc";
				reg = <0xf080 0x10>;
				interrupt-controller;
				#interrupt-cells = <0x02>;
				amlogic,channel-interrupts = <0x40 0x41 0x42 0x43 0x44 0x45 0x46 0x47>;
				status = "okay";
				phandle = <0xe2>;
			};

			meson_clk_msr {
				compatible = "amlogic, gxl_measure";
				reg = <0x18004 0x04 0x1800c 0x04>;
			};

			pwm@1b000 {
				compatible = "amlogic,g12b-ee-pwm";
				reg = <0x1b000 0x20>;
				#pwm-cells = <0x03>;
				clocks = <0x2d 0x2d 0x2d 0x2d>;
				clock-names = "clkin0\0clkin1\0clkin2\0clkin3";
				status = "okay";
				phandle = <0x72>;
			};

			pwm@1a000 {
				compatible = "amlogic,g12b-ee-pwm";
				reg = <0x1a000 0x20>;
				#pwm-cells = <0x03>;
				clocks = <0x2d 0x2d 0x2d 0x2d>;
				clock-names = "clkin0\0clkin1\0clkin2\0clkin3";
				status = "disabled";
				phandle = <0xe3>;
			};

			pwm@19000 {
				compatible = "amlogic,g12b-ee-pwm";
				reg = <0x19000 0x20>;
				#pwm-cells = <0x03>;
				clocks = <0x2d 0x2d 0x2d 0x2d>;
				clock-names = "clkin0\0clkin1\0clkin2\0clkin3";
				status = "okay";
				phandle = <0x7a>;
			};

			i2c@1f000 {
				compatible = "amlogic,meson-g12b-i2c";
				status = "disabled";
				reg = <0x1f000 0x20>;
				interrupts = <0x00 0x15 0x01 0x00 0x5b 0x01>;
				#address-cells = <0x01>;
				#size-cells = <0x00>;
				clocks = <0x13 0x2a>;
				clock-names = "clk_i2c";
				pinctrl-names = "default";
				pinctrl-0 = <0x30>;
				clock-frequency = <0x61a80>;
				phandle = <0xe4>;

				touchscreen@5d {
					compatible = "goodix,gt9xx";
					status = "disabled";
					reg = <0x5d>;
					reset-gpio = <0x2c 0x0a 0x00>;
					irq-gpio = <0x2c 0x04 0x00>;
					goodix,cfg-group0 = [41 00 04 58 02 05 0c 00 02 54 07 0f 50 2d 03 05 00 00 00 00 40 00 04 20 10 f3 aa 07 28 0a 2c 2e 7c 06 00 00 00 c9 03 24 00 01 00 00 00 00 ff 5d 66 98 32 28 64 94 c5 02 08 00 00 01 91 2c 00 8a 34 00 8a 3f 00 7e 4c 00 78 5b 00 78 00 00 00 00 00 00 00 00 00 00 00 00 00 00 00 00 00 00 00 00 00 00 00 00 00 00 00 00 00 00 00 00 00 00 00 00 02 04 06 08 0a 0c 0e 10 12 14 ff ff ff ff 00 00 00 00 00 00 00 00 00 00 00 00 00 00 00 00 00 02 04 06 08 0a 0c 1d 1e 1f 20 21 22 24 26 ff ff ff ff ff ff ff ff ff ff ff 00 00 00 00 00 00 00 00 00 00 00 00 00 00 00 00 e3 01];
				};

				touchscreen@38 {
					compatible = "focaltech,fts";
					status = "disabled";
					reg = <0x38>;
					reset-gpio = <0x2c 0x0a 0x00>;
					irq-gpio = <0x2c 0x04 0x00>;
					x_max = <0x500>;
					y_max = <0x2d0>;
					rotation = <0x01>;
					max-touch-number = <0x0a>;
				};
			};

			i2c@1e000 {
				compatible = "amlogic,meson-g12b-i2c";
				status = "disabled";
				reg = <0x1e000 0x20>;
				interrupts = <0x00 0xd6 0x01 0x00 0x5c 0x01>;
				#address-cells = <0x01>;
				#size-cells = <0x00>;
				clocks = <0x13 0x2a>;
				clock-names = "clk_i2c";
				phandle = <0xe5>;
			};

			i2c@1d000 {
				compatible = "amlogic,meson-g12b-i2c";
				status = "okay";
				reg = <0x1d000 0x20>;
				interrupts = <0x00 0xd7 0x01 0x00 0x5e 0x01>;
				#address-cells = <0x01>;
				#size-cells = <0x00>;
				clocks = <0x13 0x2a>;
				clock-names = "clk_i2c";
				pinctrl-names = "default";
				pinctrl-0 = <0x31>;
				clock-frequency = <0x186a0>;
				phandle = <0xe6>;

				sensor-i2c@6c {
					compatible = "arm, i2c-sensor";
					reg = <0x6c>;
					reg-names = "i2c-sensor";
					slave-addr = <0x6c>;
					reg-type = <0x02>;
					reg-data-type = <0x01>;
					link-device = <0x32>;
				};
			};

			i2c@1c000 {
				compatible = "amlogic,meson-g12b-i2c";
				status = "okay";
				reg = <0x1c000 0x20>;
				interrupts = <0x00 0x27 0x01 0x00 0x5f 0x01>;
				#address-cells = <0x01>;
				#size-cells = <0x00>;
				clocks = <0x13 0x2a>;
				clock-names = "clk_i2c";
				pinctrl-names = "default";
				pinctrl-0 = <0x33>;
				clock-frequency = <0x186a0>;
				phandle = <0xe7>;

				ad82584f_62@62 {
					compatible = "ESMT, ad82584f";
					#sound-dai-cells = <0x00>;
					reg = <0x31>;
					status = "okay";
					reset_pin = <0x2c 0x37 0x00>;
					no_mclk;
					phandle = <0x9e>;
				};

				tlv320adc3101_32@32 {
					compatible = "ti,tlv320adc3101";
					#sound-dai-cells = <0x00>;
					reg = <0x19>;
					differential_pair = <0x01>;
					status = "disabled";
					phandle = <0xe8>;
				};

				bl_extern_i2c {
					compatible = "bl_extern, i2c";
					dev_name = "lp8556";
					reg = <0x2c>;
					status = "disabled";
				};
			};

			spi@13000 {
				compatible = "amlogic,meson-g12b-spicc\0amlogic,meson-g12a-spicc";
				reg = <0x13000 0x44>;
				interrupts = <0x00 0x51 0x04>;
				clocks = <0x13 0x29 0x13 0xd1>;
				clock-names = "core\0comp";
				#address-cells = <0x01>;
				#size-cells = <0x00>;
				status = "disabled";
				phandle = <0xe9>;
			};

			spi@15000 {
				compatible = "amlogic,meson-g12b-spicc\0amlogic,meson-g12a-spicc";
				reg = <0x15000 0x44>;
				interrupts = <0x00 0x5a 0x04>;
				clocks = <0x13 0x2f 0x13 0xd5>;
				clock-names = "core\0comp";
				#address-cells = <0x01>;
				#size-cells = <0x00>;
				status = "disabled";
				phandle = <0xea>;
			};
		};

		// GPIO中断控制器
		aobus@ff800000 {
			compatible = "simple-bus";
			reg = <0xff800000 0xb000>;
			#address-cells = <0x01>;
			#size-cells = <0x01>;
			ranges = <0x00 0xff800000 0xb000>;
			phandle = <0xeb>;

			cpu_version {
				reg = <0x220 0x04>;
			};

			clock-controller@0 {
				compatible = "amlogic,g12b-aoclkc";
				#clock-cells = <0x01>;
				#reset-cells = <0x01>;
				reg = <0x00 0x320>;
				phandle = <0xec>;
			};

			pwm@7000 {
				compatible = "amlogic,g12b-ao-pwm";
				reg = <0x7000 0x20>;
				#pwm-cells = <0x03>;
				clocks = <0x2d 0x2d 0x2d 0x2d>;
				clock-names = "clkin0\0clkin1\0clkin2\0clkin3";
				status = "disabled";
				phandle = <0xed>;
			};

			pwm@2000 {
				compatible = "amlogic,g12b-ao-pwm";
				reg = <0x2000 0x20>;
				#pwm-cells = <0x03>;
				clocks = <0x2d 0x2d 0x2d 0x2d>;
				clock-names = "clkin0\0clkin1\0clkin2\0clkin3";
				status = "okay";
				phandle = <0x70>;
			};

			i2c@5000 {
				compatible = "amlogic,meson-g12b-i2c";
				status = "disabled";
				reg = <0x5000 0x20>;
				interrupts = <0x00 0xc3 0x01 0x00 0xc9 0x01>;
				#address-cells = <0x01>;
				#size-cells = <0x00>;
				clocks = <0x13 0x2a>;
				clock-names = "clk_i2c";
				phandle = <0xee>;
			};

			i2c_slave@6000 {
				compatible = "amlogic, meson-i2c-slave";
				status = "disabled";
				reg = <0x6000 0x20>;
				interrupts = <0x00 0xc2 0x01>;
				pinctrl-names = "default";
				pinctrl-0 = <0x34>;
				phandle = <0xef>;
			};

			serial@3000 {
				compatible = "amlogic, meson-uart";
				reg = <0x3000 0x18>;
				interrupts = <0x00 0xc1 0x01>;
				status = "okay";
				clocks = <0x2d>;
				clock-names = "clk_uart";
				xtal_tick_en = <0x02>;
				fifosize = <0x40>;
				pinctrl-names = "default";
				support-sysrq = <0x00>;
				phandle = <0xf0>;
			};

			serial@4000 {
				compatible = "amlogic, meson-uart";
				reg = <0x4000 0x18>;
				interrupts = <0x00 0xc5 0x01>;
				status = "disabled";
				clocks = <0x2d>;
				clock-names = "clk_uart";
				fifosize = <0x40>;
				pinctrl-names = "default";
				pinctrl-0 = <0x35>;
				phandle = <0xf1>;
			};

			meson-irblaster@14c {
				compatible = "amlogic, meson_irblaster";
				reg = <0x14c 0x10 0x40 0x04>;
				#irblaster-cells = <0x02>;
				interrupts = <0x00 0xc6 0x01>;
				status = "disabled";
				phandle = <0xf2>;
			};
		};

		// 外设控制总线
		periphs@ff634400 {
			compatible = "simple-bus";
			reg = <0xff634400 0x400>;
			#address-cells = <0x01>;
			#size-cells = <0x01>;
			ranges = <0x00 0xff634400 0x400>;
			phandle = <0xf3>;
		};

		// hiubus总线控制器
		hiubus@ff63c000 {
			compatible = "simple-bus";
			reg = <0xff63c000 0x2000>;
			#address-cells = <0x01>;
			#size-cells = <0x01>;
			ranges = <0x00 0xff63c000 0x2000>;
			phandle = <0xf4>;

			clock-controller@0 {
				compatible = "amlogic,g12b-clkc-1";
				#clock-cells = <0x01>;
				reg = <0x00 0x3dc>;
				phandle = <0x13>;
			};

			clock-controller@1 {
				compatible = "amlogic,g12b-clkc-2";
				#clock-cells = <0x01>;
				reg = <0x00 0x3dc>;
				phandle = <0xf5>;
			};
		};

		// ‌ion_dev内存管理模块
		ion_dev {
			compatible = "amlogic, ion_dev";
			memory-region = <0x36>;
		};

		// ‌audiobus音频子系统
		audiobus@0xff642000 {
			compatible = "amlogic, audio-controller\0simple-bus";
			reg = <0xff642000 0x2000>;
			#address-cells = <0x01>;
			#size-cells = <0x01>;
			ranges = <0x00 0xff642000 0x2000>;
			phandle = <0xf6>;

			audio_clocks {
				compatible = "amlogic, g12a-audio-clocks";
				#clock-cells = <0x01>;
				reg = <0x00 0xb0>;
				phandle = <0x37>;
			};

			ddr_manager {
				compatible = "amlogic, g12a-audio-ddr-manager";
				interrupts = <0x00 0x94 0x01 0x00 0x95 0x01 0x00 0x96 0x01 0x00 0x98 0x01 0x00 0x99 0x01 0x00 0x9a 0x01>;
				interrupt-names = "toddr_a\0toddr_b\0toddr_c\0frddr_a\0frddr_b\0frddr_c";
			};

			tdma {
				compatible = "amlogic, g12a-snd-tdma";
				#sound-dai-cells = <0x00>;
				dai-tdm-lane-slot-mask-in = <0x00 0x01>;
				dai-tdm-oe-lane-slot-mask-out = <0x01 0x00>;
				dai-tdm-clk-sel = <0x00>;
				clocks = <0x37 0x17 0x13 0x0c>;
				clock-names = "mclk\0clk_srcpll";
				pinctrl-names = "tdm_pins";
				pinctrl-0 = <0x38 0x39>;
				phandle = <0x9a>;
			};

			tdmb {
				compatible = "amlogic, g12a-snd-tdmb";
				#sound-dai-cells = <0x00>;
				dai-tdm-lane-slot-mask-in = <0x00 0x01 0x00 0x00>;
				dai-tdm-lane-slot-mask-out = <0x01 0x00 0x00 0x00>;
				dai-tdm-clk-sel = <0x01>;
				clocks = <0x37 0x18 0x13 0x0d 0x13 0x0c 0x37 0x1e>;
				clock-names = "mclk\0clk_srcpll\0samesource_srcpll\0samesource_clk";
				pinctrl-names = "tdm_pins";
				pinctrl-0 = <0x3a 0x3b 0x3c>;
				mclk_pad = <0x00>;
				samesource_sel = <0x03>;
				phandle = <0x9c>;
			};

			tdmc {
				compatible = "amlogic, g12a-snd-tdmc";
				#sound-dai-cells = <0x00>;
				dai-tdm-lane-slot-mask-in = <0x01 0x00 0x00 0x00>;
				#dai-tdm-lane-slot-mask-out = <0x01 0x00 0x01 0x01>;
				#dai-tdm-lane-oe-slot-mask-in = <0x00 0x00 0x00 0x00>;
				#dai-tdm-lane-oe-slot-mask-out = <0x01 0x00 0x00 0x00>;
				dai-tdm-clk-sel = <0x02>;
				clocks = <0x37 0x19 0x13 0x0e>;
				clock-names = "mclk\0clk_srcpll";
				pinctrl-names = "tdm_pins";
				pinctrl-0 = <0x3d 0x3e 0x3f>;
				mclk_pad = <0x01>;
				phandle = <0x9f>;
			};

			tdm@3 {
				compatible = "amlogic, g12a-snd-tdmlb";
				#sound-dai-cells = <0x00>;
				dai-tdm-lane-lb-slot-mask-in = <0x01 0x00 0x00 0x00>;
				dai-tdm-clk-sel = <0x01>;
				clocks = <0x37 0x18 0x13 0x0d>;
				clock-names = "mclk\0clk_srcpll";
				lb-src-sel = <0x01>;
				status = "disabled";
				phandle = <0xf7>;
			};

			spdif {
				compatible = "amlogic, g12a-snd-spdif-a";
				#sound-dai-cells = <0x00>;
				clocks = <0x13 0x0c 0x13 0x04 0x37 0x10 0x37 0x11 0x37 0x1d 0x37 0x1e>;
				clock-names = "sysclk\0fixed_clk\0gate_spdifin\0gate_spdifout\0clk_spdifin\0clk_spdifout";
				interrupts = <0x00 0x97 0x01>;
				interrupt-names = "irq_spdifin";
				pinctrl-names = "spdif_pins\0spdif_pins_mute";
				pinctrl-0 = <0x40>;
				pinctrl-1 = <0x41>;
				status = "okay";
				phandle = <0xa1>;
			};

			spdif_b {
				compatible = "amlogic, g12a-snd-spdif-b";
				#sound-dai-cells = <0x00>;
				clocks = <0x13 0x0c 0x37 0x15 0x37 0x21>;
				clock-names = "sysclk\0gate_spdifout\0clk_spdifout";
				status = "disabled";
				phandle = <0xf8>;
			};

			pdm {
				compatible = "amlogic, g12a-snd-pdm";
				#sound-dai-cells = <0x00>;
				clocks = <0x37 0x01 0x13 0x03 0x13 0x0f 0x37 0x1f 0x37 0x20>;
				clock-names = "gate\0sysclk_srcpll\0dclk_srcpll\0pdm_dclk\0pdm_sysclk";
				pinctrl-names = "pdm_pins";
				pinctrl-0 = <0x42>;
				filter_mode = <0x01>;
				status = "okay";
				phandle = <0xa0>;
			};

			loopback@0 {
				compatible = "amlogic, g12a-loopback";
				#sound-dai-cells = <0x00>;
				clocks = <0x37 0x01 0x13 0x03 0x13 0x0f 0x37 0x1f 0x37 0x20 0x13 0x0c 0x37 0x17>;
				clock-names = "pdm_gate\0pdm_sysclk_srcpll\0pdm_dclk_srcpll\0pdm_dclk\0pdm_sysclk\0tdminlb_mpll\0tdminlb_mclk";
				datain_src = <0x04>;
				datain_chnum = <0x04>;
				datain_chmask = <0x0f>;
				datain-lane-mask-in = <0x01 0x00 0x01 0x00>;
				mclk-fs = <0x100>;
				datalb_src = <0x01>;
				datalb_chnum = <0x02>;
				datalb_chmask = <0x03>;
				datalb-lane-mask-in = <0x01 0x00 0x00 0x00>;
				status = "okay";
				phandle = <0xa2>;
			};

			resample {
				compatible = "amlogic, g12a-resample";
				clocks = <0x13 0x0f 0x37 0x1c 0x37 0x24>;
				clock-names = "resample_pll\0resample_src\0resample_clk";
				resample_module = <0x04>;
				status = "disabled";
				phandle = <0xf9>;
			};

			pwrdet {
				compatible = "amlogic, g12a-power-detect";
				interrupts = <0x00 0x9b 0x01>;
				interrupt-names = "pwrdet_irq";
				pwrdet_src = <0x04>;
				hi_th = <0x70000>;
				lo_th = <0x16000>;
				status = "disabled";
				phandle = <0xfa>;
			};
		};

		// DMA控制器
		aml_dma {
			compatible = "amlogic,aml_txlx_dma";
			reg = <0xff63e000 0x48>;
			interrupts = <0x00 0xb4 0x01>;

			aml_aes {
				compatible = "amlogic,aes_g12a_dma";
				dev_name = "aml_aes_dma";
				status = "okay";
			};

			aml_sha {
				compatible = "amlogic,sha_dma";
				dev_name = "aml_sha_dma";
				status = "okay";
			};

			aml_tdes {
				compatible = "amlogic,tdes_dma";
				dev_name = "aml_tdes_dma";
				status = "okay";
			};
		};
	};

	// 红外遥控
	rc@0xff808040 {
		compatible = "amlogic, aml_remote";
		dev_name = "meson-remote";
		reg = <0xff808040 0x44 0xff808000 0x20>;
		status = "okay";
		protocol = <0x01>;
		interrupts = <0x00 0xc4 0x01>;
		pinctrl-names = "default";
		pinctrl-0 = <0x43>;
		map = <0x44>;
		max_frame_time = <0xc8>;
		phandle = <0xfb>;
	};

	// 红外遥控
	custom_maps {
		mapnum = <0x03>;
		map0 = <0x45>;
		map1 = <0x46>;
		map2 = <0x47>;
		phandle = <0x44>;

		map_0 {
			mapname = "amlogic-remote-1";
			customcode = <0xfb04>;
			release_delay = <0x50>;
			size = <0x32>;
			keymap = <0x47000b 0x130002 0x100003 0x110004 0xf0005 0xc0006 0xd0007 0xb0008 0x80009 0x9000a 0x5c0061 0x51003d 0x50003e 0x40003f 0x4d0040 0x430041 0x170042 0x43 0x10044 0x160057 0x49000e 0x60082 0x140083 0x440067 0x1d006c 0x1c0069 0x48006a 0x53007d 0x450068 0x19006d 0x520077 0x5007a 0x59007b 0x1b0078 0x40079 0x1a0074 0xa000f 0xe0071 0x1f0066 0x1e0084 0x70085 0x120086 0x540087 0x20088 0x4f001e 0x420030 0x5d002e 0x4c0020 0x580089 0x55008c>;
			phandle = <0x45>;
		};

		map_1 {
			mapname = "amlogic-remote-2";
			customcode = <0xfe01>;
			release_delay = <0x50>;
			size = <0x35>;
			keymap = <0x10002 0x20003 0x30004 0x40005 0x50006 0x60007 0x70008 0x80009 0x9000a 0xa000b 0x1f01d2 0x15008b 0x16000f 0xc0192 0xd0193 0xe0073 0xf0072 0x110066 0x1c006a 0x1b0069 0x190067 0x1a006c 0x1d001c 0x170071 0x4900db 0x43009e 0x1201d5 0x1401d6 0x1801d7 0x590166 0x5a00a6 0x100074 0x4200a5 0x4400a3 0x1e00a8 0x4b00d0 0x5800a4 0x460082 0x400083 0x380046 0x5701d0 0x5b01d1 0x54018e 0x4c018f 0x4e0190 0x550191 0x5300ed 0x5200ee 0x3900d4 0x4100d5 0xb00d6 0xd8 0x1300d9>;
			phandle = <0x46>;
		};

		map_2 {
			mapname = "dangbei-remote";
			customcode = <0x281>;
			release_delay = <0x50>;
			size = <0x0f>;
			keymap = <0x10074 0x2003e 0x30067 0x40069 0x50061 0x6006a 0x7006c 0x8009e 0x90066 0xa008b 0xb0073 0xc0072 0xd0040 0xe007d 0xff003d>;
			phandle = <0x47>;
		};
	};

	// 主串口/UART0
	serial@ffd24000 {
		compatible = "amlogic, meson-uart";
		reg = <0xffd24000 0x18>;
		interrupts = <0x00 0x1a 0x01>;
		status = "okay";
		clocks = <0x2d 0x13 0x2e>;
		clock-names = "clk_uart\0clk_gate";
		fifosize = <0x80>;
		pinctrl-names = "default";
		pinctrl-0 = <0x48>;
		phandle = <0xfc>;
	};

    // UART1
	serial@ffd23000 {
		compatible = "amlogic, meson-uart";
		reg = <0xffd23000 0x18>;
		interrupts = <0x00 0x4b 0x01>;
		status = "disabled";
		clocks = <0x2d 0x13 0x3c>;
		clock-names = "clk_uart\0clk_gate";
		fifosize = <0x40>;
		pinctrl-names = "default";
		pinctrl-0 = <0x49>;
		phandle = <0xfd>;
	};

	// UART2
	serial@ffd22000 {
		compatible = "amlogic, meson-uart";
		reg = <0xffd22000 0x18>;
		interrupts = <0x00 0x5d 0x01>;
		status = "disabled";
		clocks = <0x2d 0x13 0x3c>;
		clock-names = "clk_uart\0clk_gate";
		fifosize = <0x40>;
		pinctrl-names = "default";
		pinctrl-0 = <0x4a>;
		phandle = <0xfe>;
	};

	// PCIe控制器配置
	pcieA@fc000000 {
		compatible = "amlogic, amlogic-pcie-v2\0snps,dw-pcie";
		reg = <0xfc000000 0x400000 0xff648000 0x2000 0xfc400000 0x200000 0xff646000 0x2000 0xffd01080 0x10>;
		reg-names = "elbi\0cfg\0config\0phy\0reset";
		interrupts = <0x00 0xdd 0x00>;
		#interrupt-cells = <0x01>;
		bus-range = <0x00 0xff>;
		#address-cells = <0x03>;
		#size-cells = <0x02>;
		interrupt-map-mask = <0x00 0x00 0x00 0x00>;
		interrupt-map = <0x00 0x00 0x00 0x00 0x01 0x00 0xdf 0x01>;
		device_type = "pci";
		ranges = <0x81000000 0x00 0x00 0xfc600000 0x00 0x100000 0x82000000 0x00 0xfc700000 0xfc700000 0x00 0x1900000>;
		num-lanes = <0x01>;
		pcie-num = <0x01>;
		clocks = <0x13 0x18 0x13 0x3f 0x13 0x42>;
		clock-names = "pcie_refpll\0pcie\0pcie_phy";
		gpio-type = <0x02>;
		pcie-apb-rst-bit = <0x0f>;
		pcie-phy-rst-bit = <0x0e>;
		pcie-ctrl-a-rst-bit = <0x0c>;
		status = "disable";
		reset-gpio = <0x2c 0x49 0x00>;
		phandle = <0xff>;
	};

	// HDMI发射器配置‌
	amhdmitx {
		compatible = "amlogic, amhdmitx";
		dev_name = "amhdmitx";
		status = "okay";
		vend-data = <0x4b>;
		pinctrl-names = "default\0hdmitx_i2c";
		pinctrl-0 = <0x4c 0x4d>;
		pinctrl-1 = <0x4e 0x4f>;
		clocks = <0x13 0x55 0x13 0x4e 0x13 0x4f 0x13 0x95 0x13 0x8c>;
		clock-names = "venci_top_gate\0venci_0_gate\0venci_1_gate\0hdmi_vapb_clk\0hdmi_vpu_clk";
		interrupts = <0x00 0x39 0x01>;
		interrupt-names = "hdmitx_hpd";
		ic_type = <0x0b>;
		phandle = <0x100>;

		vend_data {
			vendor_name = "Amlogic";
			product_desc = "MBox Meson Ref";
			vendor_id = <0x00>;
			phandle = <0x4b>;
		};
	};

	// Prime从设备配置‌
	amprime_sl {
		compatible = "amlogic, prime_sl_g12";
		dev_name = "amprime_sl";
		status = "disabled";
		phandle = <0x101>;
	};

	// GPU/NPU加速器
	galcore {
		compatible = "amlogic, galcore";
		dev_name = "galcore";
		status = "okay";
		clocks = <0x13 0xe8 0x13 0xe7>;
		clock-names = "cts_vipnanoq_axi_clk_composite\0cts_vipnanoq_core_clk_composite";
		interrupts = <0x00 0x93 0x04>;
		interrupt-names = "galcore";
		reg = <0xff100000 0x800 0xff000000 0x400000 0xff63c10c 0x04 0xff63c110 0x04 0xffd01088 0x04 0xff63c1c8 0x04>;
		reg-names = "NN_REG\0NN_SRAM\0NN_MEM0\0NN_MEM1\0NN_RESET\0NN_CLK";
		nn_power_version = <0x02>;
		nn_efuse = <0xff63003c 0x20>;
		memory-region = <0x50>;
	};

	// HDMI CEC控制器
	aocec {
		compatible = "amlogic, aocec-g12a";
		device_name = "aocec";
		status = "okay";
		vendor_name = "Amlogic";
		vendor_id = <0x00>;
		product_desc = "G12B";
		cec_osd_string = "AML_MBOX";
		port_num = <0x01>;
		ee_cec;
		arc_port_mask = <0x02>;
		interrupts = <0x00 0xcb 0x01 0x00 0xc7 0x01>;
		interrupt-names = "hdmi_aocecb\0hdmi_aocec";
		pinctrl-names = "default\0hdmitx_aocecb\0cec_pin_sleep";
		pinctrl-0 = <0x51>;
		pinctrl-1 = <0x52>;
		pinctrl-2 = <0x52>;
		reg = <0xff80023c 0x04 0xff800000 0x400 0xff634400 0x26>;
		reg-names = "ao_exit\0ao\0periphs";
		phandle = <0x102>;
	};

	// 视频输入模块0
	vdin0 {
		compatible = "amlogic, vdin";
		dev_name = "vdin0";
		status = "okay";
		reserve-iomap = "true";
		flag_cma = <0x00>;
		interrupts = <0x00 0x53 0x01>;
		rdma-irq = <0x02>;
		vdin_id = <0x00>;
		memory-region = <0x53>;
		tv_bit_mode = <0x15>;
		phandle = <0x103>;
	};

	// 视频输入模块1
	vdin1 {
		compatible = "amlogic, vdin";
		dev_name = "vdin1";
		status = "okay";
		reserve-iomap = "true";
		flag_cma = <0x00>;
		interrupts = <0x00 0x55 0x01>;
		rdma-irq = <0x04>;
		vdin_id = <0x01>;
		memory-region = <0x54>;
		tv_bit_mode = <0x01>;
		phandle = <0x104>;
	};

	// 视频输出模块1
	vout {
		compatible = "amlogic, vout";
		dev_name = "vout";
		status = "okay";
	};

	// 视频输出模块2
	vout2 {
		compatible = "amlogic, vout2";
		dev_name = "vout";
		status = "okay";
		clocks = <0x13 0xc4 0x13 0xc9>;
		clock-names = "vpu_clkc0\0vpu_clkc";
	};

	// 视频数模转换器
	vdac {
		compatible = "amlogic, vdac-g12b";
		status = "okay";
	};

	// ‌画布管理
	canvas {
		compatible = "amlogic, meson, canvas";
		dev_name = "amlogic-canvas";
		status = "okay";
		reg = <0xff638000 0x2000>;
		phandle = <0x105>;
	};

	// ‌图像处理引擎
	ge2d {
		compatible = "amlogic, ge2d-g12a";
		dev_name = "ge2d";
		status = "okay";
		interrupts = <0x00 0x92 0x01>;
		interrupt-names = "ge2d";
		clocks = <0x13 0x95 0x13 0x3d 0x13 0x96>;
		clock-names = "clk_vapb_0\0clk_ge2d\0clk_ge2d_gate";
		reg = <0xff940000 0x10000>;
	};

	// 视频显示管理模块
	meson-amvideom {
		compatible = "amlogic, amvideom";
		dev_name = "amvideom";
		status = "okay";
		interrupts = <0x00 0x03 0x01>;
		interrupt-names = "vsync";
	};

	// 多媒体编解码基础模块，管理总线地址映射。
	codec_io {
		compatible = "amlogic, codec_io";
		status = "okay";
		#address-cells = <0x01>;
		#size-cells = <0x01>;
		ranges;
		phandle = <0x106>;

		io_cbus_base {
			reg = <0xffd00000 0x100000>;
		};

		io_dos_base {
			reg = <0xff620000 0x10000>;
		};

		io_hiubus_base {
			reg = <0xff63c000 0x2000>;
		};

		io_aobus_base {
			reg = <0xff800000 0x10000>;
		};

		io_vcbus_base {
			reg = <0xff900000 0x40000>;
		};

		io_dmc_base {
			reg = <0xff638000 0x2000>;
		};

		io_efuse_base {
			reg = <0xff630000 0x2000>;
		};
	};

	// 图形变形矫正模块
	gdc {
		#address-cells = <0x01>;
		#size-cells = <0x01>;
		status = "ok";
		compatible = "amlogic, g12b-gdc";
		reg = <0xff950000 0x100 0xff63c16c 0x04 0xff63c100 0x04>;
		interrupts = <0x00 0x90 0x01>;
		interrupt-names = "GDC";
		clocks = <0x13 0xe5 0x13 0xe6>;
		clock-names = "core\0axi";
		phandle = <0x107>;
	};

	// 视频流处理模块
	mesonstream {
		compatible = "amlogic, codec, streambuf";
		dev_name = "mesonstream";
		status = "okay";
		clocks = <0x13 0x40 0x13 0x39 0x13 0x43 0x13 0x22 0x13 0xa5 0x13 0xae 0x13 0xb7 0x13 0xc0>;
		clock-names = "parser_top\0demux\0ahbarb0\0vdec\0clk_vdec_mux\0clk_hcodec_mux\0clk_hevc_mux\0clk_hevcb_mux";
	};

	// 视频解码器，支持多格式硬解，配置多路邮箱中断。
	vdec {
		compatible = "amlogic, vdec";
		dev_name = "vdec.0";
		status = "okay";
		interrupts = <0x00 0x03 0x01 0x00 0x17 0x01 0x00 0x20 0x01 0x00 0x2b 0x01 0x00 0x2c 0x01 0x00 0x2d 0x01>;
		interrupt-names = "vsync\0demux\0parser\0mailbox_0\0mailbox_1\0mailbox_2";
	};

	// H.264视频编码器。
	amvenc_avc {
		compatible = "amlogic, amvenc_avc";
		dev_name = "amvenc_avc";
		status = "okay";
		interrupts = <0x00 0x2d 0x01>;
		interrupt-names = "mailbox_2";
	};

	// HEVC视频编码器。
	hevc_enc {
		compatible = "cnm, HevcEnc";
		dev_name = "HevcEnc";
		status = "okay";
		interrupts = <0x00 0xbb 0x01>;
		interrupt-names = "wave420l_irq";
		#address-cells = <0x01>;
		#size-cells = <0x01>;
		ranges;

		io_reg_base {
			reg = <0xff610000 0x4000>;
		};
	};

	// ‌RDMA模块
	rdma {
		compatible = "amlogic, meson-g12b, rdma";
		dev_name = "amlogic-rdma";
		status = "okay";
		interrupts = <0x00 0x59 0x01>;
		interrupt-names = "rdma";
	};

	// ‌显示帧缓冲模块
	meson-fb {
		compatible = "amlogic, meson-g12b";
		memory-region = <0x55>;
		dev_name = "meson-fb";
		status = "okay";
		interrupts = <0x00 0x03 0x01 0x00 0x38 0x01 0x00 0x59 0x01>;
		interrupt-names = "viu-vsync\0viu2-vsync\0rdma";
		display_mode_default = "1080p60hz";
		scale_mode = <0x01>;
		display_size_default = <0x780 0x438 0x780 0x870 0x20>;
		clocks = <0x13 0xc9>;
		clock-names = "vpu_clkc";
		mem_size = <0x800000 0x1980000 0x100000 0x100000 0x800000>;
		logo_addr = "0x7f800000";
		mem_alloc = <0x00>;
		pxp_mode = <0x00>;
		phandle = <0x108>;
	};

	// ‌eMMC控制器
	emmc@ffe07000 {
		status = "okay";
		compatible = "amlogic, meson-mmc-g12b";
		reg = <0xffe07000 0x800>;
		interrupts = <0x00 0xbf 0x01>;
		pinctrl-names = "emmc_clk_cmd_pins\0emmc_all_pins";
		pinctrl-0 = <0x56>;
		pinctrl-1 = <0x57 0x58>;
		clocks = <0x13 0x35 0x13 0x72 0x13 0x02 0x13 0x20 0x2d>;
		clock-names = "core\0clkin0\0clkin1\0clkin2\0xtal";
		bus-width = <0x08>;
		cap-sd-highspeed;
		cap-mmc-highspeed;
		max-frequency = <0xbebc200>;
		non-removable;
		disable-wp;
		phandle = <0x109>;

		emmc {
			pinname = "emmc";
			ocr_avail = <0x200080>;
			tx_delay = <0x00>;
			max_req_size = <0x20000>;
			gpio_dat3 = <0x2c 0x1d 0x00>;
			hw_reset = <0x2c 0x23 0x00>;
			card_type = <0x01>;
			caps = "MMC_CAP_8_BIT_DATA\0MMC_CAP_MMC_HIGHSPEED\0MMC_CAP_SD_HIGHSPEED\0MMC_CAP_NONREMOVABLE\0MMC_CAP_HW_RESET\0MMC_CAP_ERASE\0MMC_CAP_CMD23\0MMC_CAP_DRIVER_TYPE_A";
			caps2 = "MMC_CAP2_HS200";
			f_min = <0x61a80>;
			f_max = <0x5f5e100>;
		};
	};

	// ‌SD卡控制器
	sd@ffe05000 {
		status = "okay";
		compatible = "amlogic, meson-mmc-g12b";
		reg = <0xffe05000 0x800>;
		interrupts = <0x00 0xbe 0x01>;
		pinctrl-names = "sd_all_pins\0sd_clk_cmd_pins\0sd_1bit_pins\0sd_clk_cmd_uart_pins\0sd_1bit_uart_pins\0sd_to_ao_uart_pins\0ao_to_sd_uart_pins\0sd_to_ao_jtag_pins\0ao_to_sd_jtag_pins";
		pinctrl-0 = <0x59>;
		pinctrl-1 = <0x5a>;
		pinctrl-2 = <0x5b>;
		pinctrl-3 = <0x5c 0x5a 0x5d>;
		pinctrl-4 = <0x5c 0x5b 0x5d>;
		pinctrl-5 = <0x59 0x5e>;
		pinctrl-6 = <0x5c 0x5d>;
		pinctrl-7 = <0x59 0x5e>;
		pinctrl-8 = <0x5c 0x5d>;
		clocks = <0x13 0x34 0x13 0x6e 0x13 0x02 0x13 0x05 0x2d>;
		clock-names = "core\0clkin0\0clkin1\0clkin2\0xtal";
		bus-width = <0x04>;
		cap-sd-highspeed;
		cap-mmc-highspeed;
		max-frequency = <0x5f5e100>;
		disable-wp;
		phandle = <0x10a>;

		sd {
			pinname = "sd";
			ocr_avail = <0x200080>;
			max_req_size = <0x20000>;
			gpio_dat3 = <0x2c 0x2d 0x00>;
			jtag_pin = <0x2c 0x2b 0x00>;
			gpio_cd = <0x2c 0x30 0x00>;
			card_type = <0x05>;
			caps = "MMC_CAP_4_BIT_DATA\0MMC_CAP_MMC_HIGHSPEED\0MMC_CAP_SD_HIGHSPEED";
			f_min = <0x61a80>;
			f_max = <0x2faf080>;
		};
	};

	// 无线模块
	sdio@ffe03000 {
		status = "okay";
		compatible = "amlogic, meson-mmc-g12b";
		reg = <0xffe03000 0x800>;
		interrupts = <0x00 0xbd 0x04>;
		pinctrl-names = "sdio_all_pins\0sdio_clk_cmd_pins";
		pinctrl-0 = <0x5f>;
		pinctrl-1 = <0x60>;
		clocks = <0x13 0x33 0x13 0x6a 0x13 0x02 0x13 0x05 0x2d>;
		clock-names = "core\0clkin0\0clkin1\0clkin2\0xtal";
		bus-width = <0x04>;
		cap-sd-highspeed;
		cap-mmc-highspeed;
		max-frequency = <0x5f5e100>;
		disable-wp;
		phandle = <0x10b>;

		sdio {
			pinname = "sdio";
			ocr_avail = <0x200080>;
			max_req_size = <0x20000>;
			card_type = <0x03>;
			gpio_trigger = <0x61 0x06 0x00>;
			caps = "MMC_CAP_4_BIT_DATA\0MMC_CAP_MMC_HIGHSPEED\0MMC_CAP_SD_HIGHSPEED\0MMC_CAP_NONREMOVABLE\0MMC_CAP_UHS_SDR12\0MMC_CAP_UHS_SDR25\0MMC_CAP_UHS_SDR50\0MMC_CAP_UHS_SDR104\0MMC_PM_KEEP_POWER\0MMC_CAP_SDIO_IRQ";
			f_min = <0x61a80>;
			f_max = <0xbebc200>;
		};
	};

	// NAND Flash控制器‌
	nfc@0 {
		compatible = "amlogic, aml_mtd_nand";
		dev_name = "mtdnand";
		status = "disabled";
		reg = <0xffe07800 0x200>;
		interrupts = <0x00 0x22 0x01>;
		pinctrl-names = "nand_rb_mod\0nand_norb_mod\0nand_cs_only";
		pinctrl-0 = <0x62>;
		pinctrl-1 = <0x62>;
		pinctrl-2 = <0x63>;
		clocks = <0x13 0x35 0x13 0x72>;
		clock-names = "core\0clkin";
		device_id = <0x00>;
		bl_mode = <0x01>;
		fip_copies = <0x04>;
		fip_size = <0x200000>;
		nand_clk_ctrl = <0xffe07000>;
		plat-names = "bootloader\0nandnormal";
		plat-num = <0x02>;
		plat-part-0 = <0x64>;
		plat-part-1 = <0x65>;
		phandle = <0x10c>;

		bootloader {
			enable_pad = "ce0";
			busy_pad = "rb0";
			timming_mode = "mode5";
			bch_mode = "bch8_1k";
			t_rea = <0x14>;
			t_rhoh = <0x0f>;
			chip_num = <0x01>;
			part_num = <0x00>;
			rb_detect = <0x01>;
			phandle = <0x64>;
		};

		nandnormal {
			enable_pad = "ce0";
			busy_pad = "rb0";
			timming_mode = "mode5";
			bch_mode = "bch8_1k";
			plane_mode = "twoplane";
			t_rea = <0x14>;
			t_rhoh = <0x0f>;
			chip_num = <0x02>;
			part_num = <0x03>;
			partition = <0x66>;
			rb_detect = <0x01>;
			phandle = <0x65>;
		};

		nand_partition {
			phandle = <0x66>;

			tpl {
				offset = <0x00 0x00>;
				size = <0x00 0x00>;
			};

			logo {
				offset = <0x00 0x00>;
				size = <0x00 0x200000>;
			};

			recovery {
				offset = <0x00 0x00>;
				size = <0x00 0x1000000>;
			};

			boot {
				offset = <0x00 0x00>;
				size = <0x00 0x1000000>;
			};

			system {
				offset = <0x00 0x00>;
				size = <0x00 0x4000000>;
			};

			data {
				offset = <0xffffffff 0xffffffff>;
				size = <0x00 0x00>;
			};
		};
	};

	// 动态温控系统配置
	meson-cooldev@0 {
		status = "okay";
		compatible = "amlogic, meson-cooldev";
		device_name = "mcooldev";
		phandle = <0x10d>;

		cooling_devices {

			cpufreq_cool_cluster0 {
				min_state = <0xf4240>;
				dyn_coeff = <0x78>;
				cluster_id = <0x00>;
				gpu_pp = <0x02>;
				node_name = "cpufreq_cool0";
				device_type = "cpufreq";
			};

			cpufreq_cool_cluster1 {
				min_state = <0xf4240>;
				dyn_coeff = <0x1cc>;
				cluster_id = <0x01>;
				gpu_pp = <0x02>;
				node_name = "cpufreq_cool1";
				device_type = "cpufreq";
			};

			cpucore_cool_cluster {
				min_state = <0x01>;
				dyn_coeff = <0x00>;
				gpu_pp = <0x02>;
				node_name = "cpucore_cool";
				device_type = "cpucore";
			};

			gpufreq_cool {
				min_state = <0x190>;
				dyn_coeff = <0x166>;
				cluster_id = <0x00>;
				gpu_pp = <0x02>;
				node_name = "gpufreq_cool0";
				device_type = "gpufreq";
			};

			gpucore_cool {
				min_state = <0x01>;
				dyn_coeff = <0x00>;
				cluster_id = <0x00>;
				gpu_pp = <0x02>;
				node_name = "gpucore_cool0";
				device_type = "gpucore";
			};
		};

		cpufreq_cool0 {
			#cooling-cells = <0x02>;
			phandle = <0x69>;
		};

		cpufreq_cool1 {
			#cooling-cells = <0x02>;
			phandle = <0x6a>;
		};

		cpucore_cool {
			#cooling-cells = <0x02>;
			phandle = <0x6b>;
		};

		gpufreq_cool0 {
			#cooling-cells = <0x02>;
			phandle = <0x6c>;
		};

		gpucore_cool0 {
			#cooling-cells = <0x02>;
			phandle = <0x6d>;
		};
	};

	// SoC和DDR内存的温控管理策略‌
	thermal-zones {

		soc_thermal {
			polling-delay = <0x3e8>;
			polling-delay-passive = <0x64>;
			sustainable-power = <0xdde>;
			thermal-sensors = <0x67 0x00>;
			phandle = <0x10e>;

			trips {

				trip-point@0 {
					temperature = <0x14050>;
					hysteresis = <0x7d0>;
					type = "passive";
					phandle = <0x10f>;
				};

				trip-point@1 {
					temperature = <0x157c0>;
					hysteresis = <0x7d0>;
					type = "passive";
					phandle = <0x68>;
				};

				trip-point@2 {
					temperature = <0x17318>;
					hysteresis = <0x7d0>;
					type = "hot";
					phandle = <0x110>;
				};

				trip-point@3 {
					temperature = <0x1adb0>;
					hysteresis = <0x3e8>;
					type = "critical";
					phandle = <0x111>;
				};
			};

			cooling-maps {

				cpufreq_cooling_map0 {
					trip = <0x68>;
					cooling-device = <0x69 0x00 0x0a>;
					contribution = <0x400>;
				};

				cpufreq_cooling_map1 {
					trip = <0x68>;
					cooling-device = <0x6a 0x00 0x09>;
					contribution = <0x400>;
				};

				cpucore_cooling_map {
					trip = <0x68>;
					cooling-device = <0x6b 0x00 0x05>;
					contribution = <0x400>;
				};

				gpufreq_cooling_map {
					trip = <0x68>;
					cooling-device = <0x6c 0x00 0x04>;
					contribution = <0x400>;
				};

				gpucore_cooling_map {
					trip = <0x68>;
					cooling-device = <0x6d 0x00 0x02>;
					contribution = <0x400>;
				};
			};
		};

		ddr_thermal {
			polling-delay = <0x3e8>;
			polling-delay-passive = <0x64>;
			sustainable-power = <0xdde>;
			thermal-sensors = <0x6e 0x01>;
			phandle = <0x112>;

			trips {

				trip-point@0 {
					temperature = <0xea60>;
					hysteresis = <0x1388>;
					type = "passive";
					phandle = <0x113>;
				};

				trip-point@1 {
					temperature = <0x124f8>;
					hysteresis = <0x1388>;
					type = "passive";
					phandle = <0x114>;
				};

				trip-point@2 {
					temperature = <0x14c08>;
					hysteresis = <0x1388>;
					type = "hot";
					phandle = <0x115>;
				};

				trip-point@3 {
					temperature = <0x1adb0>;
					hysteresis = <0x3e8>;
					type = "critical";
					phandle = <0x116>;
				};
			};
		};
	};

	// 音频子系统内存映射配置
	aml_snd_iomap {
		compatible = "amlogic, snd-iomap";
		status = "okay";
		#address-cells = <0x01>;
		#size-cells = <0x01>;
		ranges;

		pdm_bus {
			reg = <0xff640000 0x2000>;
		};

		audiobus_base {
			reg = <0xff642000 0x2000>;
		};

		audiolocker_base {
			reg = <0xff64a000 0x2000>;
		};

		eqdrc_base {
			reg = <0xff656000 0x1800>;
		};

		reset_base {
			reg = <0xffd01000 0x1000>;
		};
	};

	// 基于PWM的CPU电压调节器‌
	pwmao_d-regulator {
		compatible = "pwm-regulator";
		pinctrl-names = "default";
		pinctrl-0 = <0x6f>;
		pwms = <0x70 0x01 0x5dc 0x00>;
		regulator-name = "vddcpu0";
		regulator-min-microvolt = <0xa6040>;
		regulator-max-microvolt = <0xfde80>;
		regulator-always-on;
		max-duty-cycle = <0x5dc>;
		voltage-table = <0xfde80 0x00 0xfb770 0x03 0xf9060 0x06 0xf6950 0x08 0xf4240 0x0b 0xf1b30 0x0e 0xef420 0x11 0xecd10 0x14 0xea600 0x17 0xe7ef0 0x1a 0xe57e0 0x1d 0xe30d0 0x1f 0xe09c0 0x22 0xde2b0 0x25 0xdbba0 0x28 0xd9490 0x2b 0xd6d80 0x2d 0xd4670 0x30 0xd1f60 0x33 0xcf850 0x36 0xcd140 0x38 0xcaa30 0x3b 0xc8320 0x3e 0xc5c10 0x41 0xc3500 0x44 0xc0df0 0x46 0xbe6e0 0x49 0xbbfd0 0x4c 0xb98c0 0x4f 0xb71b0 0x51 0xb4aa0 0x54 0xb2390 0x57 0xafc80 0x59 0xad570 0x5c 0xaae60 0x5f 0xa8750 0x62 0xa6040 0x64>;
		status = "okay";
		phandle = <0x22>;
	};

	// 基于PWM的CPU核心电压调节器
	pwmab_a-regulator {
		compatible = "pwm-regulator";
		pinctrl-names = "default";
		pinctrl-0 = <0x71>;
		pwms = <0x72 0x00 0x5dc 0x00>;
		regulator-name = "vddcpu1";
		regulator-min-microvolt = <0xa6040>;
		regulator-max-microvolt = <0xfde80>;
		regulator-always-on;
		max-duty-cycle = <0x5dc>;
		voltage-table = <0xfde80 0x00 0xfb770 0x03 0xf9060 0x06 0xf6950 0x08 0xf4240 0x0b 0xf1b30 0x0e 0xef420 0x11 0xecd10 0x14 0xea600 0x17 0xe7ef0 0x1a 0xe57e0 0x1d 0xe30d0 0x1f 0xe09c0 0x22 0xde2b0 0x25 0xdbba0 0x28 0xd9490 0x2b 0xd6d80 0x2d 0xd4670 0x30 0xd1f60 0x33 0xcf850 0x36 0xcd140 0x38 0xcaa30 0x3b 0xc8320 0x3e 0xc5c10 0x41 0xc3500 0x44 0xc0df0 0x46 0xbe6e0 0x49 0xbbfd0 0x4c 0xb98c0 0x4f 0xb71b0 0x51 0xb4aa0 0x54 0xb2390 0x57 0xafc80 0x59 0xad570 0x5c 0xaae60 0x5f 0xa8750 0x62 0xa6040 0x64>;
		status = "okay";
		phandle = <0x26>;
	};

	// 随机数生成器(RNG)模块
	rng {
		compatible = "amlogic,meson-rng";
		status = "okay";
		#address-cells = <0x01>;
		#size-cells = <0x01>;
		reg = <0xff630218 0x04>;
		quality = [03 e8];
	};

	// DDR带宽监控模块
	ddr_bandwidth {
		compatible = "amlogic, ddr-bandwidth";
		status = "okay";
		reg = <0xff638000 0x100 0xff638c00 0x100>;
		interrupts = <0x00 0x34 0x01>;
		interrupt-names = "ddr_bandwidth";
	};

	// DMC内存控制器监控模块
	dmc_monitor {
		compatible = "amlogic, dmc_monitor";
		status = "okay";
		reg_base = <0xff639000>;
		interrupts = <0x00 0x33 0x01>;
	};

	// ISP信号处理模块
	isp-sc@ff655400 {
		compatible = "amlogic, isp-sc";
		reg = <0xff655400 0x1000>;
		reg-names = "isp_sc";
		interrupts = <0x00 0x11 0x00>;
		interrupt-names = "isp_sc";
		phandle = <0x73>;
	};

	// ISP主控制器
	isp@ff140000 {
		compatible = "arm, isp";
		reg = <0xff140000 0x40000>;
		reg-names = "ISP";
		isp-efuse = <0xff630038 0x4000>;
		interrupts = <0x00 0x8e 0x04>;
		interrupt-names = "ISP";
		temper-buf-size = <0x18>;
		clocks = <0x13 0xea 0x13 0xeb>;
		clock-names = "cts_mipi_isp_clk_composite\0cts_mipi_csi_phy_clk0_composite";
		link-device = <0x73>;
		status = "okay";
		memory-region = <0x74>;
		phandle = <0x117>;
	};

	// ISP适配器模块
	isp-adapter@ff650000 {
		compatible = "amlogic, isp-adapter";
		reg = <0xff650000 0x6000>;
		reg-names = "adapter";
		interrupts = <0x00 0xb3 0x00>;
		interrupt-names = "adapter-irq";
		mem_alloc = <0x30>;
		status = "okay";
		memory-region = <0x75>;
		phandle = <0x76>;
	};

	// CSI-2 PHY物理层模块
	phy-csi@ff650000 {
		compatible = "amlogic, phy-csi";
		reg = <0xff650000 0x2000 0xff652000 0x2000 0xff63c300 0x100 0xff654000 0x100 0xff654400 0x100>;
		reg-names = "csi2_phy0\0csi2_phy1\0aphy_reg\0csi0_host\0csi1_host";
		interrupts = <0x00 0x29 0x00 0x00 0x2a 0x00 0x00 0x48 0x00 0x00 0x4a 0x00 0x00 0x57 0x00 0x00 0x58 0x00>;
		interrupt-names = "phy0-irq\0phy1-irq\0csi-host0-intr2\0csi-host0-intr1\0csi-host1-intr2\0csi-host1-intr1";
		link-device = <0x76>;
		phandle = <0x32>;
	};

	// 安全密钥模块
	defendkey {
		compatible = "amlogic, defendkey";
		reg = <0xff630218 0x04>;
		mem_size = <0x00 0x100000>;
		status = "okay";
		phandle = <0x118>;
	};

	// LCD显示系统配置
	lcd {
		compatible = "amlogic, lcd-g12b";
		mode = "tablet";
		status = "okay";
		key_valid = <0x00>;
		clocks = <0x13 0x24 0x13 0x31 0x13 0x9a 0x13 0x5d 0x13 0x5f 0x13 0x07>;
		clock-names = "dsi_host_gate\0dsi_phy_gate\0dsi_meas\0encl_top_gate\0encl_int_gate\0gp0_pll";
		reg = <0xffd07000 0x400 0xff644000 0x200>;
		interrupts = <0x00 0x03 0x01 0x00 0x38 0x01>;
		interrupt-names = "vsync\0vsync2";
		pinctrl_version = <0x02>;
		clk_path = <0x01>;
		resume_type = <0x00>;
		lcd_cpu-gpios = <0x2c 0x0a 0x00 0x2c 0x09 0x00>;
		lcd_cpu_gpio_names = "GPIOZ_9\0GPIOZ_8";

		lcd_0 {
			model_name = "B080XAN01";
			interface = "mipi";
			basic_setting = <0x300 0x400 0x3b4 0x474 0x08 0x77 0x9f>;
			lcd_timing = <0x40 0x38 0x00 0x32 0x1e 0x00>;
			clk_attr = <0x00 0x00 0x01 0x3dd6dc0>;
			mipi_attr = <0x04 0x226 0x00 0x01 0x00 0x02 0x01 0x00>;
			dsi_init_on = <0x05 0x01 0x11 0xfd 0x01 0x14 0x05 0x01 0x29 0xfd 0x01 0x14 0xff 0x00>;
			dsi_init_off = <0x05 0x01 0x28 0xfd 0x01 0x0a 0x05 0x01 0x10 0xfd 0x01 0x0a 0xff 0x00>;
			extern_init = <0xff>;
			power_on_step = <0x00 0x01 0x00 0x64 0x00 0x00 0x00 0x0a 0x00 0x00 0x01 0x14 0x02 0x00 0x00 0x00 0xff 0x00 0x00 0x00>;
			power_off_step = <0x02 0x00 0x00 0x32 0x00 0x00 0x00 0x0a 0x00 0x01 0x01 0x64 0xff 0x00 0x00 0x00>;
			backlight_index = <0x00>;
		};

		lcd_1 {
			model_name = "TL070WSH27";
			interface = "mipi";
			basic_setting = <0x400 0x258 0x4e2 0x276 0x08 0x9a 0x56>;
			lcd_timing = <0x50 0x64 0x00 0x05 0x14 0x00>;
			clk_attr = <0x00 0x00 0x01 0x2d0fa50>;
			mipi_attr = <0x04 0x12c 0x00 0x01 0x00 0x02 0x01 0x00>;
			dsi_init_on = <0x05 0x01 0x11 0xfd 0x01 0xc8 0x05 0x01 0x29 0xfd 0x01 0x14 0xff 0x00>;
			dsi_init_off = <0x05 0x01 0x28 0xfd 0x01 0x0a 0x05 0x01 0x10 0xfd 0x01 0x0a 0xff 0x00>;
			extern_init = <0xff>;
			power_on_step = <0x00 0x01 0x00 0x64 0x00 0x00 0x00 0x0a 0x00 0x00 0x01 0x14 0x02 0x00 0x00 0x00 0xff 0x00 0x00 0x00>;
			power_off_step = <0x02 0x00 0x00 0x32 0x00 0x00 0x00 0x0a 0x00 0x01 0x01 0x64 0xff 0x00 0x00 0x00>;
			backlight_index = <0x00>;
		};

		lcd_2 {
			model_name = "TL070HDV03CT";
			interface = "mipi";
			basic_setting = <0x2d0 0x500 0x3ca 0x554 0x08 0x57 0x9a>;
			lcd_timing = <0x0a 0x78 0x00 0x04 0x28 0x00>;
			clk_attr = <0x00 0x00 0x01 0x4bb51a8>;
			mipi_attr = <0x04 0x1f4 0x00 0x01 0x00 0x02 0x01 0x00>;
			dsi_init_on = <0xff 0x00>;
			dsi_init_off = <0xff 0x00>;
			extern_init = <0x01>;
			power_on_step = <0x00 0x01 0x00 0x64 0x00 0x00 0x00 0x0a 0x00 0x00 0x01 0x14 0x02 0x00 0x00 0x00 0xff 0x00 0x00 0x00>;
			power_off_step = <0x02 0x00 0x00 0x32 0x00 0x00 0x00 0x0a 0x00 0x01 0x01 0x64 0xff 0x00 0x00 0x00>;
			backlight_index = <0x00>;
		};

		lcd_3 {
			model_name = "P070ACB_FT";
			interface = "mipi";
			basic_setting = <0x258 0x400 0x302 0x42e 0x08 0x03 0x05>;
			lcd_timing = <0x0a 0x50 0x00 0x06 0x14 0x00>;
			clk_attr = <0x00 0x00 0x01 0x2f24d90>;
			mipi_attr = <0x04 0x190 0x00 0x01 0x00 0x02 0x00 0x00>;
			dsi_init_on = <0xff 0x0a 0xf0 0x03 0x00 0x01 0x1e 0xf0 0x03 0x00 0x00 0x0a 0xf0 0x03 0x00 0x01 0x1e 0xfc 0x02 0x04 0x03 0xff 0x00>;
			dsi_init_off = <0xff 0x00>;
			extern_init = <0x02>;
			power_on_step = <0x00 0x01 0x00 0xc8 0x02 0x00 0x00 0x00 0xff 0x00 0x00 0x00>;
			power_off_step = <0x02 0x00 0x00 0x00 0x00 0x00 0x00 0x14 0x00 0x01 0x01 0x64 0xff 0x00 0x00 0x00>;
			backlight_index = <0x00>;
		};
	};

	// 外部LCD显示控制模块配置
	lcd_extern {
		compatible = "amlogic, lcd_extern";
		status = "okay";
		i2c_bus = "i2c_bus_0";
		key_valid = <0x00>;

		extern_0 {
			index = <0x00>;
			extern_name = "mipi_default";
			status = "okay";
			type = <0x02>;
			cmd_size = <0xff>;
			init_on = <0xfd 0x01 0x0a 0x05 0x01 0x11 0xfd 0x01 0x78 0x05 0x01 0x29 0xff 0x00>;
			init_off = <0x05 0x01 0x28 0xfd 0x01 0x0a 0x05 0x01 0x10 0xfd 0x01 0x96 0xff 0x00>;
		};

		extern_1 {
			index = <0x01>;
			extern_name = "mipi_default";
			status = "okay";
			type = <0x02>;
			cmd_size = <0xff>;
			init_on = <0x39 0x04 0xff 0x98 0x81 0x03 0x15 0x02 0x01 0x00 0x15 0x02 0x02 0x00 0x15 0x02 0x03 0x72 0x15 0x02 0x04 0x00 0x15 0x02 0x05 0x00 0x15 0x02 0x06 0x09 0x15 0x02 0x07 0x00 0x15 0x02 0x08 0x00 0x15 0x02 0x09 0x01 0x15 0x02 0x0a 0x00 0x15 0x02 0x0b 0x00 0x15 0x02 0x0c 0x01 0x15 0x02 0x0d 0x00 0x15 0x02 0x0e 0x00 0x15 0x02 0x0f 0x14 0x15 0x02 0x10 0x14 0x15 0x02 0x11 0x00 0x15 0x02 0x12 0x00 0x15 0x02 0x13 0x00 0x15 0x02 0x14 0x00 0x15 0x02 0x15 0x00 0x15 0x02 0x16 0x00 0x15 0x02 0x17 0x00 0x15 0x02 0x18 0x00 0x15 0x02 0x19 0x00 0x15 0x02 0x1a 0x00 0x15 0x02 0x1b 0x00 0x15 0x02 0x1c 0x00 0x15 0x02 0x1d 0x00 0x15 0x02 0x1e 0x40 0x15 0x02 0x1f 0x80 0x15 0x02 0x20 0x05 0x15 0x02 0x21 0x02 0x15 0x02 0x22 0x00 0x15 0x02 0x23 0x00 0x15 0x02 0x24 0x00 0x15 0x02 0x25 0x00 0x15 0x02 0x26 0x00 0x15 0x02 0x27 0x00 0x15 0x02 0x28 0x33 0x15 0x02 0x29 0x02 0x15 0x02 0x2a 0x00 0x15 0x02 0x2b 0x00 0x15 0x02 0x2c 0x00 0x15 0x02 0x2d 0x00 0x15 0x02 0x2e 0x00 0x15 0x02 0x2f 0x00 0x15 0x02 0x30 0x00 0x15 0x02 0x31 0x00 0x15 0x02 0x32 0x00 0x15 0x02 0x33 0x00 0x15 0x02 0x34 0x04 0x15 0x02 0x35 0x00 0x15 0x02 0x36 0x00 0x15 0x02 0x37 0x00 0x15 0x02 0x38 0x3c 0x15 0x02 0x39 0x00 0x15 0x02 0x3a 0x00 0x15 0x02 0x3b 0x00 0x15 0x02 0x3c 0x00 0x15 0x02 0x3d 0x00 0x15 0x02 0x3e 0x00 0x15 0x02 0x3f 0x00 0x15 0x02 0x40 0x00 0x15 0x02 0x41 0x00 0x15 0x02 0x42 0x00 0x15 0x02 0x43 0x00 0x15 0x02 0x44 0x00 0x15 0x02 0x50 0x10 0x15 0x02 0x51 0x32 0x15 0x02 0x52 0x54 0x15 0x02 0x53 0x76 0x15 0x02 0x54 0x98 0x15 0x02 0x55 0xba 0x15 0x02 0x56 0x10 0x15 0x02 0x57 0x32 0x15 0x02 0x58 0x54 0x15 0x02 0x59 0x76 0x15 0x02 0x5a 0x98 0x15 0x02 0x5b 0xba 0x15 0x02 0x5c 0xdc 0x15 0x02 0x5d 0xfe 0x15 0x02 0x5e 0x00 0x15 0x02 0x5f 0x0e 0x15 0x02 0x60 0x0f 0x15 0x02 0x61 0x0c 0x15 0x02 0x62 0x0d 0x15 0x02 0x63 0x06 0x15 0x02 0x64 0x07 0x15 0x02 0x65 0x02 0x15 0x02 0x66 0x02 0x15 0x02 0x67 0x02 0x15 0x02 0x68 0x02 0x15 0x02 0x69 0x01 0x15 0x02 0x6a 0x00 0x15 0x02 0x6b 0x02 0x15 0x02 0x6c 0x15 0x15 0x02 0x6d 0x14 0x15 0x02 0x6e 0x02 0x15 0x02 0x6f 0x02 0x15 0x02 0x70 0x02 0x15 0x02 0x71 0x02 0x15 0x02 0x72 0x02 0x15 0x02 0x73 0x02 0x15 0x02 0x74 0x02 0x15 0x02 0x75 0x0e 0x15 0x02 0x76 0x0f 0x15 0x02 0x77 0x0c 0x15 0x02 0x78 0x0d 0x15 0x02 0x79 0x06 0x15 0x02 0x7a 0x07 0x15 0x02 0x7b 0x02 0x15 0x02 0x7c 0x02 0x15 0x02 0x7d 0x02 0x15 0x02 0x7e 0x02 0x15 0x02 0x7f 0x01 0x15 0x02 0x80 0x00 0x15 0x02 0x81 0x02 0x15 0x02 0x82 0x14 0x15 0x02 0x83 0x15 0x15 0x02 0x84 0x02 0x15 0x02 0x85 0x02 0x15 0x02 0x86 0x02 0x15 0x02 0x87 0x02 0x15 0x02 0x88 0x02 0x15 0x02 0x89 0x02 0x15 0x02 0x8a 0x02 0x39 0x04 0xff 0x98 0x81 0x04 0x15 0x02 0x6c 0x15 0x15 0x02 0x6e 0x2a 0x15 0x02 0x6f 0x33 0x15 0x02 0x3a 0x94 0x15 0x02 0x8d 0x14 0x15 0x02 0x87 0xba 0x15 0x02 0x26 0x76 0x15 0x02 0xb2 0xd1 0x15 0x02 0xb5 0x06 0x39 0x04 0xff 0x98 0x81 0x01 0x15 0x02 0x22 0x02 0x15 0x02 0x31 0x00 0x15 0x02 0x53 0x72 0x15 0x02 0x55 0x88 0x15 0x02 0x40 0x33 0x15 0x02 0x50 0x96 0x15 0x02 0x51 0x96 0x15 0x02 0x60 0x08 0x15 0x02 0xa0 0x08 0x15 0x02 0xa1 0x1d 0x15 0x02 0xa2 0x2a 0x15 0x02 0xa3 0x10 0x15 0x02 0xa4 0x15 0x15 0x02 0xa5 0x28 0x15 0x02 0xa6 0x1c 0x15 0x02 0xa7 0x1d 0x15 0x02 0xa8 0x7e 0x15 0x02 0xa9 0x1d 0x15 0x02 0xaa 0x29 0x15 0x02 0xab 0x6b 0x15 0x02 0xac 0x1a 0x15 0x02 0xad 0x18 0x15 0x02 0xae 0x4b 0x15 0x02 0xaf 0x20 0x15 0x02 0xb0 0x27 0x15 0x02 0xb1 0x50 0x15 0x02 0xb2 0x64 0x15 0x02 0xb3 0x39 0x15 0x02 0xc0 0x08 0x15 0x02 0xc1 0x1d 0x15 0x02 0xc2 0x2a 0x15 0x02 0xc3 0x10 0x15 0x02 0xc4 0x15 0x15 0x02 0xc5 0x28 0x15 0x02 0xc6 0x1c 0x15 0x02 0xc7 0x1d 0x15 0x02 0xc8 0x7e 0x15 0x02 0xc9 0x1d 0x15 0x02 0xca 0x29 0x15 0x02 0xcb 0x6b 0x15 0x02 0xcc 0x1a 0x15 0x02 0xcd 0x18 0x15 0x02 0xce 0x4b 0x15 0x02 0xcf 0x20 0x15 0x02 0xd0 0x27 0x15 0x02 0xd1 0x50 0x15 0x02 0xd2 0x64 0x15 0x02 0xd3 0x39 0x39 0x04 0xff 0x98 0x81 0x00 0x15 0x02 0x3a 0x77 0xfd 0x01 0x02 0x15 0x02 0x36 0x08 0x05 0x01 0x11 0xfd 0x01 0xc8 0x05 0x01 0x29 0xfd 0x01 0xc8 0xff 0x00>;
			init_off = <0x05 0x01 0x28 0xfd 0x01 0x0a 0x05 0x01 0x10 0xfd 0x01 0x96 0xff 0x00>;
		};

		extern_2 {
			index = <0x02>;
			extern_name = "mipi_default";
			status = "okay";
			type = <0x02>;
			cmd_size = <0xff>;
			init_on = <0x23 0x02 0xe0 0x00 0x23 0x02 0xe1 0x93 0x23 0x02 0xe2 0x65 0x23 0x02 0xe3 0xf8 0x23 0x02 0x80 0x03 0x23 0x02 0xe0 0x01 0x23 0x02 0x0c 0x74 0x23 0x02 0x17 0x00 0x23 0x02 0x18 0xef 0x23 0x02 0x19 0x00 0x23 0x02 0x1a 0x00 0x23 0x02 0x1b 0xef 0x23 0x02 0x1c 0x00 0x23 0x02 0x1f 0x70 0x23 0x02 0x20 0x2d 0x23 0x02 0x21 0x2d 0x23 0x02 0x22 0x7e 0x23 0x02 0x26 0xf3 0x23 0x02 0x37 0x09 0x23 0x02 0x38 0x04 0x23 0x02 0x39 0x00 0x23 0x02 0x3a 0x01 0x23 0x02 0x3c 0x90 0x23 0x02 0x3d 0xff 0x23 0x02 0x3e 0xff 0x23 0x02 0x3f 0xff 0x23 0x02 0x40 0x02 0x23 0x02 0x41 0x80 0x23 0x02 0x42 0x99 0x23 0x02 0x43 0x14 0x23 0x02 0x44 0x19 0x23 0x02 0x45 0x5a 0x23 0x02 0x4b 0x04 0x23 0x02 0x55 0x02 0x23 0x02 0x56 0x01 0x23 0x02 0x57 0x69 0x23 0x02 0x58 0x0a 0x23 0x02 0x59 0x0a 0x23 0x02 0x5a 0x2e 0x23 0x02 0x5b 0x19 0x23 0x02 0x5c 0x15 0x23 0x02 0x5d 0x77 0x23 0x02 0x5e 0x56 0x23 0x02 0x5f 0x45 0x23 0x02 0x60 0x38 0x23 0x02 0x61 0x35 0x23 0x02 0x62 0x27 0x23 0x02 0x63 0x2d 0x23 0x02 0x64 0x18 0x23 0x02 0x65 0x33 0x23 0x02 0x66 0x34 0x23 0x02 0x67 0x35 0x23 0x02 0x68 0x56 0x23 0x02 0x69 0x45 0x23 0x02 0x6a 0x4f 0x23 0x02 0x6b 0x42 0x23 0x02 0x6c 0x40 0x23 0x02 0x6d 0x34 0x23 0x02 0x6e 0x25 0x23 0x02 0x6f 0x02 0x23 0x02 0x70 0x77 0x23 0x02 0x71 0x56 0x23 0x02 0x72 0x45 0x23 0x02 0x73 0x38 0x23 0x02 0x74 0x35 0x23 0x02 0x75 0x27 0x23 0x02 0x76 0x2d 0x23 0x02 0x77 0x18 0x23 0x02 0x78 0x33 0x23 0x02 0x79 0x34 0x23 0x02 0x7a 0x35 0x23 0x02 0x7b 0x56 0x23 0x02 0x7c 0x45 0x23 0x02 0x7d 0x4f 0x23 0x02 0x7e 0x42 0x23 0x02 0x7f 0x40 0x23 0x02 0x80 0x34 0x23 0x02 0x81 0x25 0x23 0x02 0x82 0x02 0x23 0x02 0xe0 0x02 0x23 0x02 0x00 0x53 0x23 0x02 0x01 0x55 0x23 0x02 0x02 0x55 0x23 0x02 0x03 0x51 0x23 0x02 0x04 0x77 0x23 0x02 0x05 0x57 0x23 0x02 0x06 0x1f 0x23 0x02 0x07 0x4f 0x23 0x02 0x08 0x4d 0x23 0x02 0x09 0x1f 0x23 0x02 0x0a 0x4b 0x23 0x02 0x0b 0x49 0x23 0x02 0x0c 0x1f 0x23 0x02 0x0d 0x47 0x23 0x02 0x0e 0x45 0x23 0x02 0x0f 0x41 0x23 0x02 0x10 0x1f 0x23 0x02 0x11 0x1f 0x23 0x02 0x12 0x1f 0x23 0x02 0x13 0x55 0x23 0x02 0x14 0x1f 0x23 0x02 0x15 0x1f 0x23 0x02 0x16 0x52 0x23 0x02 0x17 0x55 0x23 0x02 0x18 0x55 0x23 0x02 0x19 0x50 0x23 0x02 0x1a 0x77 0x23 0x02 0x1b 0x57 0x23 0x02 0x1c 0x1f 0x23 0x02 0x1d 0x4e 0x23 0x02 0x1e 0x4c 0x23 0x02 0x1f 0x1f 0x23 0x02 0x20 0x4a 0x23 0x02 0x21 0x48 0x23 0x02 0x22 0x1f 0x23 0x02 0x23 0x46 0x23 0x02 0x24 0x44 0x23 0x02 0x25 0x40 0x23 0x02 0x26 0x1f 0x23 0x02 0x27 0x1f 0x23 0x02 0x28 0x1f 0x23 0x02 0x29 0x1f 0x23 0x02 0x2a 0x1f 0x23 0x02 0x2b 0x55 0x23 0x02 0x2c 0x12 0x23 0x02 0x2d 0x15 0x23 0x02 0x2e 0x15 0x23 0x02 0x2f 0x00 0x23 0x02 0x30 0x37 0x23 0x02 0x31 0x17 0x23 0x02 0x32 0x1f 0x23 0x02 0x33 0x08 0x23 0x02 0x34 0x0a 0x23 0x02 0x35 0x1f 0x23 0x02 0x36 0x0c 0x23 0x02 0x37 0x0e 0x23 0x02 0x38 0x1f 0x23 0x02 0x39 0x04 0x23 0x02 0x3a 0x06 0x23 0x02 0x3b 0x10 0x23 0x02 0x3c 0x1f 0x23 0x02 0x3d 0x1f 0x23 0x02 0x3e 0x1f 0x23 0x02 0x3f 0x15 0x23 0x02 0x40 0x1f 0x23 0x02 0x41 0x1f 0x23 0x02 0x42 0x13 0x23 0x02 0x43 0x15 0x23 0x02 0x44 0x15 0x23 0x02 0x45 0x01 0x23 0x02 0x46 0x37 0x23 0x02 0x47 0x17 0x23 0x02 0x48 0x1f 0x23 0x02 0x49 0x09 0x23 0x02 0x4a 0x0b 0x23 0x02 0x4b 0x1f 0x23 0x02 0x4c 0x0d 0x23 0x02 0x4d 0x0f 0x23 0x02 0x4e 0x1f 0x23 0x02 0x4f 0x05 0x23 0x02 0x50 0x07 0x23 0x02 0x51 0x11 0x23 0x02 0x52 0x1f 0x23 0x02 0x53 0x1f 0x23 0x02 0x54 0x1f 0x23 0x02 0x55 0x1f 0x23 0x02 0x56 0x1f 0x23 0x02 0x57 0x15 0x23 0x02 0x58 0x40 0x23 0x02 0x59 0x00 0x23 0x02 0x5a 0x00 0x23 0x02 0x5b 0x10 0x23 0x02 0x5c 0x14 0x23 0x02 0x5d 0x40 0x23 0x02 0x5e 0x01 0x23 0x02 0x5f 0x02 0x23 0x02 0x60 0x40 0x23 0x02 0x61 0x03 0x23 0x02 0x62 0x04 0x23 0x02 0x63 0x7a 0x23 0x02 0x64 0x7a 0x23 0x02 0x65 0x74 0x23 0x02 0x66 0x16 0x23 0x02 0x67 0xb4 0x23 0x02 0x68 0x16 0x23 0x02 0x69 0x7a 0x23 0x02 0x6a 0x7a 0x23 0x02 0x6b 0x0c 0x23 0x02 0x6c 0x00 0x23 0x02 0x6d 0x04 0x23 0x02 0x6e 0x04 0x23 0x02 0x6f 0x88 0x23 0x02 0x70 0x00 0x23 0x02 0x71 0x00 0x23 0x02 0x72 0x06 0x23 0x02 0x73 0x7b 0x23 0x02 0x74 0x00 0x23 0x02 0x75 0xbc 0x23 0x02 0x76 0x00 0x23 0x02 0x77 0x04 0x23 0x02 0x78 0x2c 0x23 0x02 0x79 0x00 0x23 0x02 0x7a 0x00 0x23 0x02 0x7b 0x00 0x23 0x02 0x7c 0x00 0x23 0x02 0x7d 0x03 0x23 0x02 0x7e 0x7b 0x23 0x02 0xe0 0x04 0x23 0x02 0x09 0x11 0x23 0x02 0x0e 0x48 0x23 0x02 0x2b 0x2b 0x23 0x02 0x2e 0x44 0x23 0x02 0xe0 0x00 0x23 0x02 0xe6 0x02 0x23 0x02 0xe7 0x0c 0x05 0x01 0x11 0xfd 0x01 0x78 0x05 0x01 0x29 0x05 0x01 0x35 0xfd 0x01 0x14 0xff 0x00>;
			init_off = <0x05 0x01 0x28 0xfd 0x01 0x0a 0x05 0x01 0x10 0xfd 0x01 0x96 0xff 0x00>;
		};
	};

	// 背光控制系统
	backlight {
		compatible = "amlogic, backlight-g12b";
		status = "okay";
		key_valid = <0x00>;
		pinctrl-names = "pwm_on\0pwm_off";
		pinctrl-0 = <0x77>;
		pinctrl-1 = <0x78>;
		pinctrl_version = <0x02>;
		bl_pwm_config = <0x79>;
		bl-gpios = <0x2c 0x15 0x00 0x2c 0x16 0x00>;
		bl_gpio_names = "GPIOH_4\0GPIOH_5";

		backlight_0 {
			index = <0x00>;
			bl_name = "backlight_pwm";
			bl_level_default_uboot_kernel = <0x64 0x64>;
			bl_level_attr = <0xff 0x0a 0x80 0x80>;
			bl_ctrl_method = <0x01>;
			bl_power_attr = <0x00 0x01 0x00 0xc8 0xc8>;
			bl_pwm_port = "PWM_F";
			bl_pwm_attr = <0x00 0xb4 0x64 0x19>;
			bl_pwm_power = <0x01 0x01 0x0a 0x0a>;
			bl_pwm_en_sequence_reverse = <0x00>;
		};

		backlight_1 {
			index = <0x01>;
			bl_name = "bl_extern";
			bl_level_default_uboot_kernel = <0x64 0x64>;
			bl_level_attr = <0xff 0x0a 0x80 0x80>;
			bl_ctrl_method = <0x04>;
			bl_power_attr = <0x01 0x01 0x00 0xc8 0xc8>;
			bl_extern_index = <0x00>;
		};
	};

	// PWM硬件配置
	bl_pwm_conf {
		phandle = <0x79>;

		pwm_channel_0 {
			pwm_port_index = <0x05>;
			pwms = <0x7a 0x01 0x7558 0x00>;
		};
	};

	// 外部背光控制模块配置
	bl_extern {
		compatible = "amlogic, bl_extern";
		status = "disabled";
		i2c_bus = "i2c_bus_3";

		extern_0 {
			index = <0x00>;
			extern_name = "i2c_lp8556";
			type = <0x00>;
			i2c_address = <0x2c>;
			dim_max_min = <0xff 0x0a>;
		};

		extern_1 {
			index = <0x01>;
			extern_name = "mipi_lt070me05";
			type = <0x02>;
			dim_max_min = <0xff 0x0a>;
		};
	};

	// ‌设备别名系统
	aliases {
		serial0 = "/soc/aobus@ff800000/serial@3000";
		serial1 = "/serial@ffd24000";
		serial2 = "/serial@ffd23000";
		serial3 = "/serial@ffd22000";
		serial4 = "/soc/aobus@ff800000/serial@4000";
		i2c0 = "/soc/cbus@ffd00000/i2c@1f000";
		i2c1 = "/soc/cbus@ffd00000/i2c@1e000";
		i2c2 = "/soc/cbus@ffd00000/i2c@1d000";
		i2c3 = "/soc/cbus@ffd00000/i2c@1c000";
		i2c4 = "/soc/aobus@ff800000/i2c@5000";
		tsensor0 = "/p_tsensor@ff634594";
		tsensor1 = "/d_tsensor@ff800228";
	};

	// 内存管理配置
	memory@00000000 {
		reg = <0x00 0xd8000000>;
		device_type = "memory";
		linux,usable-memory = <0x00 0xf5000000>;
	};

	// 外设控制模块
	reserved-memory {
		#address-cells = <0x01>;
		#size-cells = <0x01>;
		ranges;

		ramoops@0x07400000 {
			compatible = "ramoops";
			reg = <0x7400000 0x100000>;
			record-size = <0x8000>;
			console-size = <0x8000>;
			ftrace-size = <0x40000>;
		};

		linux,secmon {
			compatible = "shared-dma-pool";
			reusable;
			size = <0x400000>;
			alignment = <0x400000>;
			alloc-ranges = <0x5000000 0x400000>;
			clear-map;
			phandle = <0x27>;
		};

		linux,secos {
			status = "disable";
			compatible = "amlogic, aml_secos_memory";
			reg = <0x5300000 0x2000000>;
			no-map;
			phandle = <0x119>;
		};

		linux,meson-fb {
			compatible = "shared-dma-pool";
			reusable;
			size = <0x800000>;
			alignment = <0x400000>;
			alloc-ranges = <0x7f800000 0x800000>;
			phandle = <0x55>;
		};

		linux,ion-dev {
			compatible = "shared-dma-pool";
			reusable;
			size = <0x8000000>;
			alignment = <0x400000>;
			phandle = <0x36>;
		};

		linux,di_cma {
			compatible = "shared-dma-pool";
			reusable;
			size = <0x2800000>;
			alignment = <0x400000>;
			phandle = <0x81>;
		};

		linux,ppmgr {
			compatible = "shared-dma-pool";
			size = <0x00>;
			phandle = <0x80>;
		};

		linux,codec_mm_cma {
			compatible = "shared-dma-pool";
			reusable;
			size = <0x13400000>;
			alignment = <0x400000>;
			linux,contiguous-region;
			phandle = <0x7d>;
		};

		linux,codec_mm_reserved {
			compatible = "amlogic, codec-mm-reserved";
			size = <0x00>;
			alignment = <0x100000>;
			phandle = <0x7e>;
		};

		linux,vdin0_cma {
			compatible = "shared-dma-pool";
			reusable;
			size = <0x4000000>;
			alignment = <0x400000>;
			phandle = <0x53>;
		};

		linux,vdin1_cma {
			compatible = "shared-dma-pool";
			reusable;
			size = <0x4000000>;
			alignment = <0x400000>;
			phandle = <0x54>;
		};

		linux,galcore {
			compatible = "shared-dma-pool";
			reusable;
			size = <0x1000000>;
			alignment = <0x400000>;
			linux,contiguous-region;
			phandle = <0x50>;
		};

		linux,isp_cma {
			compatible = "shared-dma-pool";
			reusable;
			status = "okay";
			size = <0x6800000>;
			alignment = <0x400000>;
			phandle = <0x74>;
		};

		linux,adapt_cma {
			compatible = "shared-dma-pool";
			reusable;
			status = "okay";
			size = <0x1800000>;
			alignment = <0x400000>;
			phandle = <0x75>;
		};
	};

	// LED子系统配置
	gpioleds {
		compatible = "gpio-leds";
		status = "okay";

		sys_led {
			label = "sys_led";
			gpios = <0x61 0x0b 0x00>;
			default-state = "on";
		};
	};

	// ‌CVBS视频输出模块
	cvbsout {
		compatible = "amlogic, cvbsout-g12b";
		dev_name = "cvbsout";
		status = "okay";
		clocks = <0x13 0x55 0x13 0x4e 0x13 0x4f 0x13 0x57>;
		clock-names = "venci_top_gate\0venci_0_gate\0venci_1_gate\0vdac_clk_gate";
		clk_path = <0x00>;
		performance = <0x1bf0 0x09 0x1b56 0x333 0x1b12 0x8080 0x1b05 0xfd 0x1c59 0xf850 0xffff 0x00>;
		performance_sarft = <0x1bf0 0x09 0x1b56 0x333 0x1b12 0x00 0x1b05 0x09 0x1c59 0xfc48 0xffff 0x00>;
	};

	// 蓝牙设备模块
	bt-dev {
		compatible = "amlogic, bt-dev";
		dev_name = "bt-dev";
		status = "okay";
		gpio_reset = <0x2c 0x53 0x00>;
		gpio_hostwake = <0x2c 0x55 0x00>;
	};

	// ‌Wi-Fi模块
	wifi {
		compatible = "amlogic, aml_wifi";
		dev_name = "aml_wifi";
		status = "okay";
		interrupt_pin = <0x2c 0x49 0x00>;
		irq_trigger_type = "GPIO_IRQ_LOW";
		power_on_pin = <0x2c 0x48 0x00>;
		dhd_static_buf;
		pinctrl-names = "default";
		pinctrl-0 = <0x7b>;
		pwm_config = <0x7c>;
	};

	// PWM调频配置
	wifi_pwm_conf {
		phandle = <0x7c>;

		pwm_channel1_conf {
			pwms = <0x7a 0x00 0x774d 0x00>;
			duty-cycle = <0x3ba6>;
			times = <0x0a>;
		};

		pwm_channel2_conf {
			pwms = <0x7a 0x02 0x7724 0x00>;
			duty-cycle = <0x3b92>;
			times = <0x0c>;
		};
	};

	// 视频编解码专用内存区域，分配连续物理内存
	codec_mm {
		compatible = "amlogic, codec, mm";
		memory-region = <0x7d 0x7e>;
		dev_name = "codec_mm";
		status = "okay";
	};

	// 共享DMA内存池，支持图像解码重用内存
	linux,picdec {
		compatible = "shared-dma-pool";
		reusable;
		size = <0x00>;
		alignment = <0x00>;
		linux,contiguous-region;
		phandle = <0x7f>;
	};

	// 图像解码模块
	picdec {
		compatible = "amlogic, picdec";
		memory-region = <0x7f>;
		dev_name = "picdec";
		status = "okay";
	};

	// 图像后处理模块
	ppmgr {
		compatible = "amlogic, ppmgr";
		memory-region = <0x80>;
		dev_name = "ppmgr";
		status = "okay";
	};

	// 去隔行扫描模块
	deinterlace {
		compatible = "amlogic, deinterlace";
		status = "okay";
		flag_cma = <0x01>;
		memory-region = <0x81>;
		interrupts = <0x00 0x2e 0x01 0x00 0x28 0x01>;
		interrupt-names = "pre_irq\0post_irq";
		clocks = <0x13 0x9b 0x13 0x9c>;
		clock-names = "vpu_clkb_tmp_composite\0vpu_clkb_composite";
		clock-range = <0x14e 0x29b>;
		buffer-size = <0x3e2c40>;
		post-wr-support = <0x01>;
		nr10bit-support = <0x01>;
		nrds-enable = <0x01>;
		pps-enable = <0x01>;
	};

	// ‌视频内存管理
	ionvideo {
		compatible = "amlogic, ionvideo";
		dev_name = "ionvideo";
		status = "okay";
	};

	// 视频解码与显示处理单元0
	amlvideo2_0 {
		compatible = "amlogic, amlvideo2";
		dev_name = "amlvideo2";
		status = "okay";
		amlvideo2_id = <0x00>;
		cma_mode = <0x01>;
	};
	// 视频解码与显示处理单元1
	amlvideo2_1 {
		compatible = "amlogic, amlvideo2";
		dev_name = "amlvideo2";
		status = "okay";
		amlvideo2_id = <0x01>;
		cma_mode = <0x01>;
	};

	// 物理电源键控制
	gpio_keypad {
		compatible = "amlogic, gpio_keypad";
		status = "okay";
		scan_period = <0x14>;
		key_num = <0x01>;
		key_name = "power";
		key_code = <0x74>;
		key-gpios = <0x61 0x03 0x00>;
		detect_mode = <0x00>;
	};

	// 模拟电压按键检测
	adc_keypad {
		compatible = "amlogic, adc_keypad";
		status = "okay";
		key_name = "vol-\0vol+\0enter";
		key_num = <0x03>;
		io-channels = <0x82 0x02>;
		io-channel-names = "key-chan-2";
		key_chan = <0x02 0x02 0x02>;
		key_code = <0x72 0x73 0x1c>;
		key_val = <0x8f 0x10a 0x185>;
		key_tolerance = <0x28 0x28 0x28>;
	};

	// unifykey节点
	unifykey {
		compatible = "amlogic, unifykey";
		status = "ok";
		unifykey-num = <0x10>;
		unifykey-index-0 = <0x83>;
		unifykey-index-1 = <0x84>;
		unifykey-index-2 = <0x85>;
		unifykey-index-3 = <0x86>;
		unifykey-index-4 = <0x87>;
		unifykey-index-5 = <0x88>;
		unifykey-index-6 = <0x89>;
		unifykey-index-7 = <0x8a>;
		unifykey-index-8 = <0x8b>;
		unifykey-index-9 = <0x8c>;
		unifykey-index-10 = <0x8d>;
		unifykey-index-11 = <0x8e>;
		unifykey-index-12 = <0x8f>;
		unifykey-index-13 = <0x90>;
		unifykey-index-14 = <0x91>;
		unifykey-index-15 = <0x92>;
		unifykey-index-16 = <0x93>;
		unifykey-index-17 = <0x94>;

		key_0 {
			key-name = "usid";
			key-device = "normal";
			key-permit = "read\0write\0del";
			phandle = <0x83>;
		};

		key_1 {
			key-name = "mac";
			key-device = "normal";
			key-permit = "read\0write\0del";
			phandle = <0x84>;
		};

		key_2 {
			key-name = "hdcp";
			key-device = "secure";
			key-type = "sha1";
			key-permit = "read\0write\0del";
			phandle = <0x85>;
		};

		key_3 {
			key-name = "secure_boot_set";
			key-device = "efuse";
			key-permit = "write";
			phandle = <0x86>;
		};

		key_4 {
			key-name = "mac_bt";
			key-device = "normal";
			key-permit = "read\0write\0del";
			key-type = "mac";
			phandle = <0x87>;
		};

		key_5 {
			key-name = "mac_wifi";
			key-device = "normal";
			key-permit = "read\0write\0del";
			key-type = "mac";
			phandle = <0x88>;
		};

		key_6 {
			key-name = "hdcp2_tx";
			key-device = "normal";
			key-permit = "read\0write\0del";
			phandle = <0x89>;
		};

		key_7 {
			key-name = "hdcp2_rx";
			key-device = "normal";
			key-permit = "read\0write\0del";
			phandle = <0x8a>;
		};

		key_8 {
			key-name = "widevinekeybox";
			key-device = "secure";
			key-permit = "read\0write\0del";
			phandle = <0x8b>;
		};

		key_9 {
			key-name = "deviceid";
			key-device = "normal";
			key-permit = "read\0write\0del";
			phandle = <0x8c>;
		};

		key_10 {
			key-name = "hdcp22_fw_private";
			key-device = "secure";
			key-permit = "read\0write\0del";
			phandle = <0x8d>;
		};

		key_11 {
			key-name = "PlayReadykeybox25";
			key-device = "secure";
			key-permit = "read\0write\0del";
			phandle = <0x8e>;
		};

		key_12 {
			key-name = "prpubkeybox";
			key-device = "secure";
			key-permit = "read\0write\0del";
			phandle = <0x8f>;
		};

		key_13 {
			key-name = "prprivkeybox";
			key-device = "secure";
			key-permit = "read\0write\0del";
			phandle = <0x90>;
		};

		key_14 {
			key-name = "attestationkeybox";
			key-device = "secure";
			key-permit = "read\0write\0del";
			phandle = <0x91>;
		};

		key_15 {
			key-name = "netflix_mgkid";
			key-device = "secure";
			key-permit = "read\0write\0del";
			phandle = <0x92>;
		};

		key_16 {
			key-name = "eth_exphy_para";
			key-device = "normal";
			key-permit = "read\0write\0del";
			phandle = <0x93>;
		};

		key_17 {
			key-name = "attestationdevidbox";
			key-device = "secure";
			key-permit = "read\0write\0del";
			phandle = <0x94>;
		};
	};

	// efusekey节点
	efusekey {
		keynum = <0x04>;
		key0 = <0x95>;
		key1 = <0x96>;
		key2 = <0x97>;
		key3 = <0x98>;
		phandle = <0x11a>;

		key_0 {
			keyname = "mac";
			offset = <0x00>;
			size = <0x06>;
			phandle = <0x95>;
		};

		key_1 {
			keyname = "mac_bt";
			offset = <0x06>;
			size = <0x06>;
			phandle = <0x96>;
		};

		key_2 {
			keyname = "mac_wifi";
			offset = <0x0c>;
			size = <0x06>;
			phandle = <0x97>;
		};

		key_3 {
			keyname = "usid";
			offset = <0x12>;
			size = <0x10>;
			phandle = <0x98>;
		};
	};

	// 视频色彩管理模块
	amlvecm {
		compatible = "amlogic, vecm";
		dev_name = "aml_vecm";
		status = "okay";
		gamma_en = <0x00>;
		wb_en = <0x00>;
		cm_en = <0x00>;
		interrupts = <0x00 0x38 0x01>;
		interrupt-names = "vsync2";
	};

	// 杜比视界处理模块，配置为TV模式
	amdolby_vision {
		compatible = "amlogic, dolby_vision_g12a";
		dev_name = "aml_amdolby_vision_driver";
		status = "okay";
		tv_mode = <0x00>;
	};

	// 虚拟音频编解码器，用于占位或测试
	dummy {
		#sound-dai-cells = <0x00>;
		compatible = "amlogic, aml_dummy_codec";
		status = "okay";
		phandle = <0x9b>;
	};
	// T9015音频编解码器
	t9015 {
		#sound-dai-cells = <0x00>;
		compatible = "amlogic, aml_codec_T9015";
		reg = <0xff632000 0x2000>;
		is_auge_used = <0x01>;
		tdmout_index = <0x01>;
		status = "okay";
		phandle = <0x9d>;
	};

	// EQDRC音频效果器
	eqdrc {
		eqdrc_module = <0x01>;
		lane_mask = <0x01>;
		channel_mask = <0x03>;
		phandle = <0x99>;
	};

	// AUGE音频卡
	auge_sound {
		compatible = "amlogic, g12a-sound-card";
		aml-audio-card,name = "AML-AUGESOUND";
		avout_mute-gpios = <0x61 0x02 0x00>;
		aml-audio-card,effect = <0x99>;

		aml-audio-card,dai-link@0 {
			format = "dsp_a";
			mclk-fs = <0x200>;
			suffix-name = "alsaPORT-pcm";

			cpu {
				sound-dai = <0x9a>;
				dai-tdm-slot-tx-mask = <0x01 0x01 0x01 0x01 0x01 0x01 0x01 0x01>;
				dai-tdm-slot-rx-mask = <0x01 0x01 0x01 0x01 0x01 0x01 0x01 0x01>;
				dai-tdm-slot-num = <0x08>;
				dai-tdm-slot-width = <0x20>;
				system-clock-frequency = <0x1770000>;
				phandle = <0x11b>;
			};

			codec {
				sound-dai = <0x9b 0x9b>;
				phandle = <0x11c>;
			};
		};

		aml-audio-card,dai-link@1 {
			format = "i2s";
			mclk-fs = <0x100>;
			continuous-clock;
			bitclock-master = <0x9c>;
			frame-master = <0x9c>;
			suffix-name = "alsaPORT-i2s";

			cpu {
				sound-dai = <0x9c>;
				dai-tdm-slot-tx-mask = <0x01 0x01>;
				dai-tdm-slot-rx-mask = <0x01 0x01>;
				dai-tdm-slot-num = <0x02>;
				dai-tdm-slot-width = <0x20>;
				system-clock-frequency = <0xbb8000>;
			};

			codec {
				sound-dai = <0x9b 0x9b 0x9d 0x9e>;
				phandle = <0x11d>;
			};
		};

		aml-audio-card,dai-link@2 {
			format = "i2s";
			mclk-fs = <0x100>;
			bitclock-master = <0x9f>;
			frame-master = <0x9f>;

			cpu {
				sound-dai = <0x9f>;
				dai-tdm-slot-tx-mask = <0x01 0x01>;
				dai-tdm-slot-rx-mask = <0x01 0x01>;
				dai-tdm-slot-num = <0x02>;
				dai-tdm-slot-width = <0x20>;
				system-clock-frequency = <0xbb8000>;
			};

			codec {
				sound-dai = <0x9b 0x9b>;
			};
		};

		aml-audio-card,dai-link@3 {
			mclk-fs = <0x40>;
			suffix-name = "alsaPORT-pdm";

			cpu {
				sound-dai = <0xa0>;
			};

			codec {
				sound-dai = <0x9b>;
			};
		};

		aml-audio-card,dai-link@4 {
			mclk-fs = <0x80>;
			continuous-clock;
			suffix-name = "alsaPORT-spdif";

			cpu {
				sound-dai = <0xa1>;
				system-clock-frequency = <0x5dc000>;
			};

			codec {
				sound-dai = <0x9b>;
			};
		};

		aml-audio-card,dai-link@6 {
			mclk-fs = <0x100>;
			continuous-clock;
			suffix-name = "alsaPORT-loopback";

			cpu {
				sound-dai = <0xa2>;
				system-clock-frequency = <0xbb8000>;
			};

			codec {
				sound-dai = <0x9b>;
			};
		};
	};

	// 音频锁相环
	locker {
		compatible = "amlogic, audiolocker";
		clocks = <0x37 0x22 0x37 0x23 0x37 0x1a 0x37 0x1b 0x13 0x0d 0x13 0x0e>;
		clock-names = "lock_out\0lock_in\0out_src\0in_src\0out_calc\0in_ref";
		interrupts = <0x00 0x01 0x01>;
		interrupt-names = "irq";
		frequency = <0x2ebae40>;
		dividor = <0x31>;
		status = "okay";
		phandle = <0x11e>;
	};

	// 第一组CPU性能状态参数
	cpu_opp_table0 {
		compatible = "operating-points-v2";
		opp-shared;
		phandle = <0x21>;

		opp00 {
			opp-hz = <0x00 0x1dcd6500>;
			opp-microvolt = <0xb2390>;
		};

		opp01 {
			opp-hz = <0x00 0x27c19cc0>;
			opp-microvolt = <0xb2390>;
		};

		opp02 {
			opp-hz = <0x00 0x3b9aca00>;
			opp-microvolt = <0xb98c0>;
		};

		opp03 {
			opp-hz = <0x00 0x47868c00>;
			opp-microvolt = <0xbe6e0>;
		};

		opp04 {
			opp-hz = <0x00 0x5353c980>;
			opp-microvolt = <0xc5c10>;
		};

		opp05 {
			opp-hz = <0x00 0x5a1f4a00>;
			opp-microvolt = <0xd1f60>;
		};

		opp06 {
			opp-hz = <0x00 0x5fd82200>;
			opp-microvolt = <0xdbba0>;
		};

		opp07 {
			opp-hz = <0x00 0x6590fa00>;
			opp-microvolt = <0xea600>;
		};

		opp08 {
			opp-hz = <0x00 0x6b49d200>;
			opp-microvolt = <0xf9060>;
		};
	};

	// 第二组CPU性能状态参数
	cpu_opp_table1 {
		compatible = "operating-points-v2";
		opp-shared;
		phandle = <0x25>;

		opp00 {
			opp-hz = <0x00 0x1dcd6500>;
			opp-microvolt = <0xb2390>;
		};

		opp01 {
			opp-hz = <0x00 0x27c19cc0>;
			opp-microvolt = <0xb2390>;
		};

		opp02 {
			opp-hz = <0x00 0x3b9aca00>;
			opp-microvolt = <0xb2390>;
		};

		opp03 {
			opp-hz = <0x00 0x47868c00>;
			opp-microvolt = <0xb71b0>;
		};

		opp04 {
			opp-hz = <0x00 0x5353c980>;
			opp-microvolt = <0xbbfd0>;
		};

		opp05 {
			opp-hz = <0x00 0x5a1f4a00>;
			opp-microvolt = <0xbbfd0>;
		};

		opp06 {
			opp-hz = <0x00 0x5fd82200>;
			opp-microvolt = <0xbe6e0>;
		};

		opp07 {
			opp-hz = <0x00 0x6590fa00>;
			opp-microvolt = <0xc0df0>;
		};

		opp08 {
			opp-hz = <0x00 0x6b49d200>;
			opp-microvolt = <0xcaa30>;
		};

		opp09 {
			opp-hz = <0x00 0x6b49d200>;
			opp-microvolt = <0xcaa30>;
		};

		opp10 {
			opp-hz = <0x00 0x6b49d200>;
			opp-microvolt = <0xcaa30>;
		};

		opp11 {
			opp-hz = <0x00 0x6b49d200>;
			opp-microvolt = <0xcaa30>;
		};

		opp12 {
			opp-hz = <0x00 0x6b49d200>;
			opp-microvolt = <0xcaa30>;
		};
	};

	// Amlogic专用CPU调频控制器
	cpufreq-meson {
		compatible = "amlogic, cpufreq-meson";
		status = "okay";
	};

	// 图形传感器
	sensor {
		compatible = "soc, sensor";
		status = "disabled";
		sensor-name = "os08a10";
		pinctrl-names = "default";
		pinctrl-0 = <0xa3>;
		clocks = <0x13 0xd7>;
		clock-names = "g12a_24m";
		reset = <0x2c 0x0d 0x00>;
		ir_cut_gpio = <0x2c 0x0c 0x00 0x2c 0x08 0x00>;
		phandle = <0x11f>;
	};

	// 图像质量（IQ）模块相关的硬件组件
	iq {
		compatible = "soc, iq";
		status = "disabled";
		sensor-name = "os08a10";
		phandle = <0x120>;
	};

	// 符号表
	__symbols__ {
		partitions = "/partitions";
		logo = "/partitions/logo";
		recovery = "/partitions/recovery";
		misc = "/partitions/misc";
		dtbo = "/partitions/dtbo";
		cri_data = "/partitions/cri_data";
		rsv = "/partitions/rsv";
		metadata = "/partitions/metadata";
		vbmeta = "/partitions/vbmeta";
		param = "/partitions/param";
		boot = "/partitions/boot";
		tee = "/partitions/tee";
		vendor = "/partitions/vendor";
		odm = "/partitions/odm";
		system = "/partitions/system";
		product = "/partitions/product";
		cache = "/partitions/cache";
		data = "/partitions/data";
		gpu = "/bifrost";
		dvfs125_cfg = "/bifrost/clk125_cfg";
		dvfs250_cfg = "/bifrost/dvfs250_cfg";
		dvfs285_cfg = "/bifrost/dvfs285_cfg";
		dvfs400_cfg = "/bifrost/dvfs400_cfg";
		dvfs500_cfg = "/bifrost/dvfs500_cfg";
		dvfs666_cfg = "/bifrost/dvfs666_cfg";
		dvfs800_cfg = "/bifrost/dvfs800_cfg";
		dvfs850_cfg = "/bifrost/dvfs850_cfg";
		CPU_COST_A73 = "/energy-costs/core-cost0";
		CPU_COST_A53 = "/energy-costs/core-cost1";
		CLUSTER_COST_A73 = "/energy-costs/cluster-cost0";
		CLUSTER_COST_A53 = "/energy-costs/cluster-cost1";
		cpus = "/cpus";
		cluster0 = "/cpus/cpu-map/cluster0";
		cluster1 = "/cpus/cpu-map/cluster1";
		CPU0 = "/cpus/cpu@0";
		CPU1 = "/cpus/cpu@1";
		CPU2 = "/cpus/cpu@100";
		CPU3 = "/cpus/cpu@101";
		CPU4 = "/cpus/cpu@102";
		CPU5 = "/cpus/cpu@103";
		CPU_SLEEP_0 = "/cpus/idle-states/cpu-sleep-0";
		CLUSTER_SLEEP_0 = "/cpus/idle-states/cluster-sleep-0";
		gic = "/interrupt-controller@2c001000";
		mailbox = "/mhu@c883c400";
		xtal = "/xtal-clk";
		ethmac = "/ethernet@ff3f0000";
		pinctrl_aobus = "/pinctrl@ff800014";
		gpio_ao = "/pinctrl@ff800014/ao-bank@ff800014";
		ao_uart_pins = "/pinctrl@ff800014/ao_uart";
		ao_b_uart_pins = "/pinctrl@ff800014/ao_b_uart";
		ao_i2c_master_pins1 = "/pinctrl@ff800014/ao_i2c_pins1";
		ao_i2c_master_pins2 = "/pinctrl@ff800014/ao_i2c_pins2";
		ao_i2c_slave_pins = "/pinctrl@ff800014/ao_i2c_slave_pins";
		pwm_ao_a_pins = "/pinctrl@ff800014/pwm_ao_a";
		pwm_ao_a_hiz_pins = "/pinctrl@ff800014/pwm_ao_a_hiz";
		pwm_ao_b_pins = "/pinctrl@ff800014/pwm_ao_b";
		pwm_ao_c_pins1 = "/pinctrl@ff800014/pwm_ao_c_pins1";
		pwm_ao_c_pins2 = "/pinctrl@ff800014/pwm_ao_c_pins2";
		pwm_ao_c_hiz_pins = "/pinctrl@ff800014/pwm_ao_c_hiz";
		pwm_ao_d_pins1 = "/pinctrl@ff800014/pwm_ao_d_pins1";
		pwm_ao_d_pins2 = "/pinctrl@ff800014/pwm_ao_d_pins2";
		pwm_ao_d_pins3 = "/pinctrl@ff800014/pwm_ao_d_pins3";
		aocec_a = "/pinctrl@ff800014/ao_ceca";
		aocec_b = "/pinctrl@ff800014/ao_cecb";
		pwm_a_e2 = "/pinctrl@ff800014/pwm_a_e2";
		jtag_apao_pins = "/pinctrl@ff800014/jtag_apao_pin";
		sd_to_ao_uart_clr_pins = "/pinctrl@ff800014/sd_to_ao_uart_clr_pins";
		sd_to_ao_uart_pins = "/pinctrl@ff800014/sd_to_ao_uart_pins";
		remote_pins = "/pinctrl@ff800014/remote_pin";
		irblaster_pins = "/pinctrl@ff800014/irblaster_pin";
		irblaster_pins1 = "/pinctrl@ff800014/irblaster_pin1";
		spdifout = "/pinctrl@ff800014/spdifout";
		spdifout_a_mute = "/pinctrl@ff800014/spdifout_a_mute";
		pinctrl_periphs = "/pinctrl@ff634480";
		gpio = "/pinctrl@ff634480/banks@ff6346c0";
		emmc_clk_cmd_pins = "/pinctrl@ff634480/emmc_clk_cmd_pins";
		emmc_conf_pull_up = "/pinctrl@ff634480/emmc_conf_pull_up";
		emmc_conf_pull_done = "/pinctrl@ff634480/emmc_conf_pull_done";
		sd_clk_cmd_pins = "/pinctrl@ff634480/sd_clk_cmd_pins";
		sd_all_pins = "/pinctrl@ff634480/sd_all_pins";
		sd_1bit_pins = "/pinctrl@ff634480/sd_1bit_pins";
		ao_to_sd_uart_pins = "/pinctrl@ff634480/ao_to_sd_uart_pins";
		sdio_clk_cmd_pins = "/pinctrl@ff634480/sdio_clk_cmd_pins";
		sdio_all_pins = "/pinctrl@ff634480/sdio_all_pins";
		all_nand_pins = "/pinctrl@ff634480/all_nand_pins";
		nand_cs_pins = "/pinctrl@ff634480/nand_cs";
		i2c0_master_pins1 = "/pinctrl@ff634480/i2c0_pins1";
		i2c0_master_pins2 = "/pinctrl@ff634480/i2c0_pins2";
		i2c0_master_pins3 = "/pinctrl@ff634480/i2c0_pins3";
		i2c1_master_pins1 = "/pinctrl@ff634480/i2c1_pins1";
		i2c1_master_pins2 = "/pinctrl@ff634480/i2c1_pins2";
		i2c1_master_pins3 = "/pinctrl@ff634480/i2c1_pins3";
		i2c2_master_pins1 = "/pinctrl@ff634480/i2c2_pins1";
		i2c2_master_pins2 = "/pinctrl@ff634480/i2c2_pins2";
		i2c3_master_pins1 = "/pinctrl@ff634480/i2c3_pins1";
		i2c3_master_pins2 = "/pinctrl@ff634480/i2c3_pins2";
		pwm_a_pins = "/pinctrl@ff634480/pwm_a";
		pwm_b_pins1 = "/pinctrl@ff634480/pwm_b_pins1";
		pwm_b_pins2 = "/pinctrl@ff634480/pwm_b_pins2";
		pwm_b_pins3 = "/pinctrl@ff634480/pwm_b_pins3";
		pwm_b_pins4 = "/pinctrl@ff634480/pwm_b_pins4";
		pwm_b_pins5 = "/pinctrl@ff634480/pwm_b_pins5";
		pwm_c_pins1 = "/pinctrl@ff634480/pwm_c_pins1";
		pwm_c_pins2 = "/pinctrl@ff634480/pwm_c_pins2";
		pwm_c_pins3 = "/pinctrl@ff634480/pwm_c_pins3";
		pwm_c_pins4 = "/pinctrl@ff634480/pwm_c_pins4";
		pwm_d_pins1 = "/pinctrl@ff634480/pwm_d_pins1";
		pwm_d_pins2 = "/pinctrl@ff634480/pwm_d_pins2";
		pwm_d_pins3 = "/pinctrl@ff634480/pwm_d_pins3";
		pwm_d_pins4 = "/pinctrl@ff634480/pwm_d_pins4";
		pwm_e_pins = "/pinctrl@ff634480/pwm_e";
		pwm_f_pins1 = "/pinctrl@ff634480/pwm_f_pins1";
		pwm_f_pins2 = "/pinctrl@ff634480/pwm_f_pins2";
		pwm_f_pins3 = "/pinctrl@ff634480/pwm_f_pins3";
		pwm_f_pins4 = "/pinctrl@ff634480/pwm_f_pins4";
		spicc0_pins_x = "/pinctrl@ff634480/spicc0_pins_x";
		spicc1_pins = "/pinctrl@ff634480/spicc1_pins";
		a_uart_pins = "/pinctrl@ff634480/a_uart";
		b_uart_pins = "/pinctrl@ff634480/b_uart";
		c_uart_pins = "/pinctrl@ff634480/c_uart";
		hdmitx_hpd = "/pinctrl@ff634480/hdmitx_hpd";
		hdmitx_hpd_gpio = "/pinctrl@ff634480/hdmitx_hpd_gpio";
		hdmitx_ddc = "/pinctrl@ff634480/hdmitx_ddc";
		eecec_a = "/pinctrl@ff634480/ee_ceca";
		eecec_b = "/pinctrl@ff634480/ee_cecb";
		internal_eth_pins = "/pinctrl@ff634480/internal_eth_pins";
		external_eth_pins = "/pinctrl@ff634480/external_eth_pins";
		irblaster_pins2 = "/pinctrl@ff634480/irblaster_pins2";
		irblaster_pins3 = "/pinctrl@ff634480/irblaster_pins3";
		jtag_apee_pins = "/pinctrl@ff634480/jtag_apee_pin";
		tdmout_a = "/pinctrl@ff634480/tdmout_a";
		tdmin_a = "/pinctrl@ff634480/tdmin_a";
		tdmb_mclk = "/pinctrl@ff634480/tdmb_mclk";
		tdmout_b = "/pinctrl@ff634480/tdmout_b";
		tdmin_b = "/pinctrl@ff634480/tdmin_b";
		tdmc_mclk = "/pinctrl@ff634480/tdmc_mclk";
		tdmout_c = "/pinctrl@ff634480/tdmout_c";
		tdmin_c = "/pinctrl@ff634480/tdmin_c";
		spdifin = "/pinctrl@ff634480/spdifin";
		pdmin = "/pinctrl@ff634480/pdmin";
		bl_pwm_off_pins = "/pinctrl@ff634480/bl_pwm_off_pin";
		clk12_24_z_pins = "/pinctrl@ff634480/clk12_24_z_pins";
		audio_data = "/audio_data";
		dwc3 = "/dwc3@ff500000";
		usb2_phy_v2 = "/usb2phy@ffe09000";
		usb3_phy_v2 = "/usb3phy@ffe09080";
		dwc2_a = "/dwc2_a@ff400000";
		wdt = "/watchdog@0xffd0f0d0";
		saradc = "/saradc";
		p_tsensor = "/p_tsensor@ff634594";
		d_tsensor = "/d_tsensor@ff800228";
		cbus = "/soc/cbus@ffd00000";
		gpio_intc = "/soc/cbus@ffd00000/interrupt-controller@f080";
		pwm_ab = "/soc/cbus@ffd00000/pwm@1b000";
		pwm_cd = "/soc/cbus@ffd00000/pwm@1a000";
		pwm_ef = "/soc/cbus@ffd00000/pwm@19000";
		i2c0 = "/soc/cbus@ffd00000/i2c@1f000";
		i2c1 = "/soc/cbus@ffd00000/i2c@1e000";
		i2c2 = "/soc/cbus@ffd00000/i2c@1d000";
		i2c3 = "/soc/cbus@ffd00000/i2c@1c000";
		ad82584f_62 = "/soc/cbus@ffd00000/i2c@1c000/ad82584f_62@62";
		tlv320adc3101_32 = "/soc/cbus@ffd00000/i2c@1c000/tlv320adc3101_32@32";
		spicc0 = "/soc/cbus@ffd00000/spi@13000";
		spicc1 = "/soc/cbus@ffd00000/spi@15000";
		aobus = "/soc/aobus@ff800000";
		aoclkc = "/soc/aobus@ff800000/clock-controller@0";
		pwm_AO_ab = "/soc/aobus@ff800000/pwm@7000";
		pwm_AO_cd = "/soc/aobus@ff800000/pwm@2000";
		i2c_AO = "/soc/aobus@ff800000/i2c@5000";
		i2c_AO_slave = "/soc/aobus@ff800000/i2c_slave@6000";
		uart_AO = "/soc/aobus@ff800000/serial@3000";
		uart_AO_B = "/soc/aobus@ff800000/serial@4000";
		irblaster = "/soc/aobus@ff800000/meson-irblaster@14c";
		periphs = "/soc/periphs@ff634400";
		hiubus = "/soc/hiubus@ff63c000";
		clkc = "/soc/hiubus@ff63c000/clock-controller@0";
		clkc_b = "/soc/hiubus@ff63c000/clock-controller@1";
		audiobus = "/soc/audiobus@0xff642000";
		clkaudio = "/soc/audiobus@0xff642000/audio_clocks";
		aml_tdma = "/soc/audiobus@0xff642000/tdma";
		aml_tdmb = "/soc/audiobus@0xff642000/tdmb";
		aml_tdmc = "/soc/audiobus@0xff642000/tdmc";
		tdmlb = "/soc/audiobus@0xff642000/tdm@3";
		aml_spdif = "/soc/audiobus@0xff642000/spdif";
		aml_spdif_b = "/soc/audiobus@0xff642000/spdif_b";
		aml_pdm = "/soc/audiobus@0xff642000/pdm";
		loopback = "/soc/audiobus@0xff642000/loopback@0";
		audioresample = "/soc/audiobus@0xff642000/resample";
		aml_pwrdet = "/soc/audiobus@0xff642000/pwrdet";
		remote = "/rc@0xff808040";
		custom_maps = "/custom_maps";
		map_0 = "/custom_maps/map_0";
		map_1 = "/custom_maps/map_1";
		map_2 = "/custom_maps/map_2";
		uart_A = "/serial@ffd24000";
		uart_B = "/serial@ffd23000";
		uart_C = "/serial@ffd22000";
		pcie_A = "/pcieA@fc000000";
		amhdmitx = "/amhdmitx";
		vend_data = "/amhdmitx/vend_data";
		amprime_sl = "/amprime_sl";
		aocec = "/aocec";
		vdin0 = "/vdin0";
		vdin1 = "/vdin1";
		canvas = "/canvas";
		codec_io = "/codec_io";
		gdc = "/gdc";
		meson_fb = "/meson-fb";
		sd_emmc_c = "/emmc@ffe07000";
		sd_emmc_b = "/sd@ffe05000";
		sd_emmc_a = "/sdio@ffe03000";
		nand = "/nfc@0";
		bootloader = "/nfc@0/bootloader";
		nandnormal = "/nfc@0/nandnormal";
		nand_partitions = "/nfc@0/nand_partition";
		meson_cooldev = "/meson-cooldev@0";
		cpufreq_cool0 = "/meson-cooldev@0/cpufreq_cool0";
		cpufreq_cool1 = "/meson-cooldev@0/cpufreq_cool1";
		cpucore_cool = "/meson-cooldev@0/cpucore_cool";
		gpufreq_cool0 = "/meson-cooldev@0/gpufreq_cool0";
		gpucore_cool0 = "/meson-cooldev@0/gpucore_cool0";
		soc_thermal = "/thermal-zones/soc_thermal";
		pswitch_on = "/thermal-zones/soc_thermal/trips/trip-point@0";
		pcontrol = "/thermal-zones/soc_thermal/trips/trip-point@1";
		phot = "/thermal-zones/soc_thermal/trips/trip-point@2";
		pcritical = "/thermal-zones/soc_thermal/trips/trip-point@3";
		ddr_thermal = "/thermal-zones/ddr_thermal";
		dswitch_on = "/thermal-zones/ddr_thermal/trips/trip-point@0";
		dcontrol = "/thermal-zones/ddr_thermal/trips/trip-point@1";
		dhot = "/thermal-zones/ddr_thermal/trips/trip-point@2";
		dcritical = "/thermal-zones/ddr_thermal/trips/trip-point@3";
		vddcpu0 = "/pwmao_d-regulator";
		vddcpu1 = "/pwmab_a-regulator";
		isp_sc = "/isp-sc@ff655400";
		isp = "/isp@ff140000";
		adapter = "/isp-adapter@ff650000";
		phycsi = "/phy-csi@ff650000";
		defendkey = "/defendkey";
		bl_pwm_conf = "/bl_pwm_conf";
		secmon_reserved = "/reserved-memory/linux,secmon";
		secos_reserved = "/reserved-memory/linux,secos";
		logo_reserved = "/reserved-memory/linux,meson-fb";
		ion_cma_reserved = "/reserved-memory/linux,ion-dev";
		di_cma_reserved = "/reserved-memory/linux,di_cma";
		ppmgr_reserved = "/reserved-memory/linux,ppmgr";
		codec_mm_cma = "/reserved-memory/linux,codec_mm_cma";
		codec_mm_reserved = "/reserved-memory/linux,codec_mm_reserved";
		vdin0_cma_reserved = "/reserved-memory/linux,vdin0_cma";
		vdin1_cma_reserved = "/reserved-memory/linux,vdin1_cma";
		galcore_reserved = "/reserved-memory/linux,galcore";
		isp_cma_reserved = "/reserved-memory/linux,isp_cma";
		adapt_cma_reserved = "/reserved-memory/linux,adapt_cma";
		wifi_pwm_conf = "/wifi_pwm_conf";
		picdec_cma_reserved = "/linux,picdec";
		keysn_0 = "/unifykey/key_0";
		keysn_1 = "/unifykey/key_1";
		keysn_2 = "/unifykey/key_2";
		keysn_3 = "/unifykey/key_3";
		keysn_4 = "/unifykey/key_4";
		keysn_5 = "/unifykey/key_5";
		keysn_6 = "/unifykey/key_6";
		keysn_7 = "/unifykey/key_7";
		keysn_8 = "/unifykey/key_8";
		keysn_9 = "/unifykey/key_9";
		keysn_10 = "/unifykey/key_10";
		keysn_11 = "/unifykey/key_11";
		keysn_12 = "/unifykey/key_12";
		keysn_13 = "/unifykey/key_13";
		keysn_14 = "/unifykey/key_14";
		keysn_15 = "/unifykey/key_15";
		keysn_16 = "/unifykey/key_16";
		keysn_17 = "/unifykey/key_17";
		efusekey = "/efusekey";
		key_0 = "/efusekey/key_0";
		key_1 = "/efusekey/key_1";
		key_2 = "/efusekey/key_2";
		key_3 = "/efusekey/key_3";
		dummy_codec = "/dummy";
		pdm_codec = "/dummy";
		amlogic_codec = "/t9015";
		audio_effect = "/eqdrc";
		tdmacpu = "/auge_sound/aml-audio-card,dai-link@0/cpu";
		tdmacodec = "/auge_sound/aml-audio-card,dai-link@0/codec";
		tdmbcodec = "/auge_sound/aml-audio-card,dai-link@1/codec";
		audiolocker = "/locker";
		cpu_opp_table0 = "/cpu_opp_table0";
		cpu_opp_table1 = "/cpu_opp_table1";
		sensor = "/sensor";
		iq = "/iq";
	};
};
